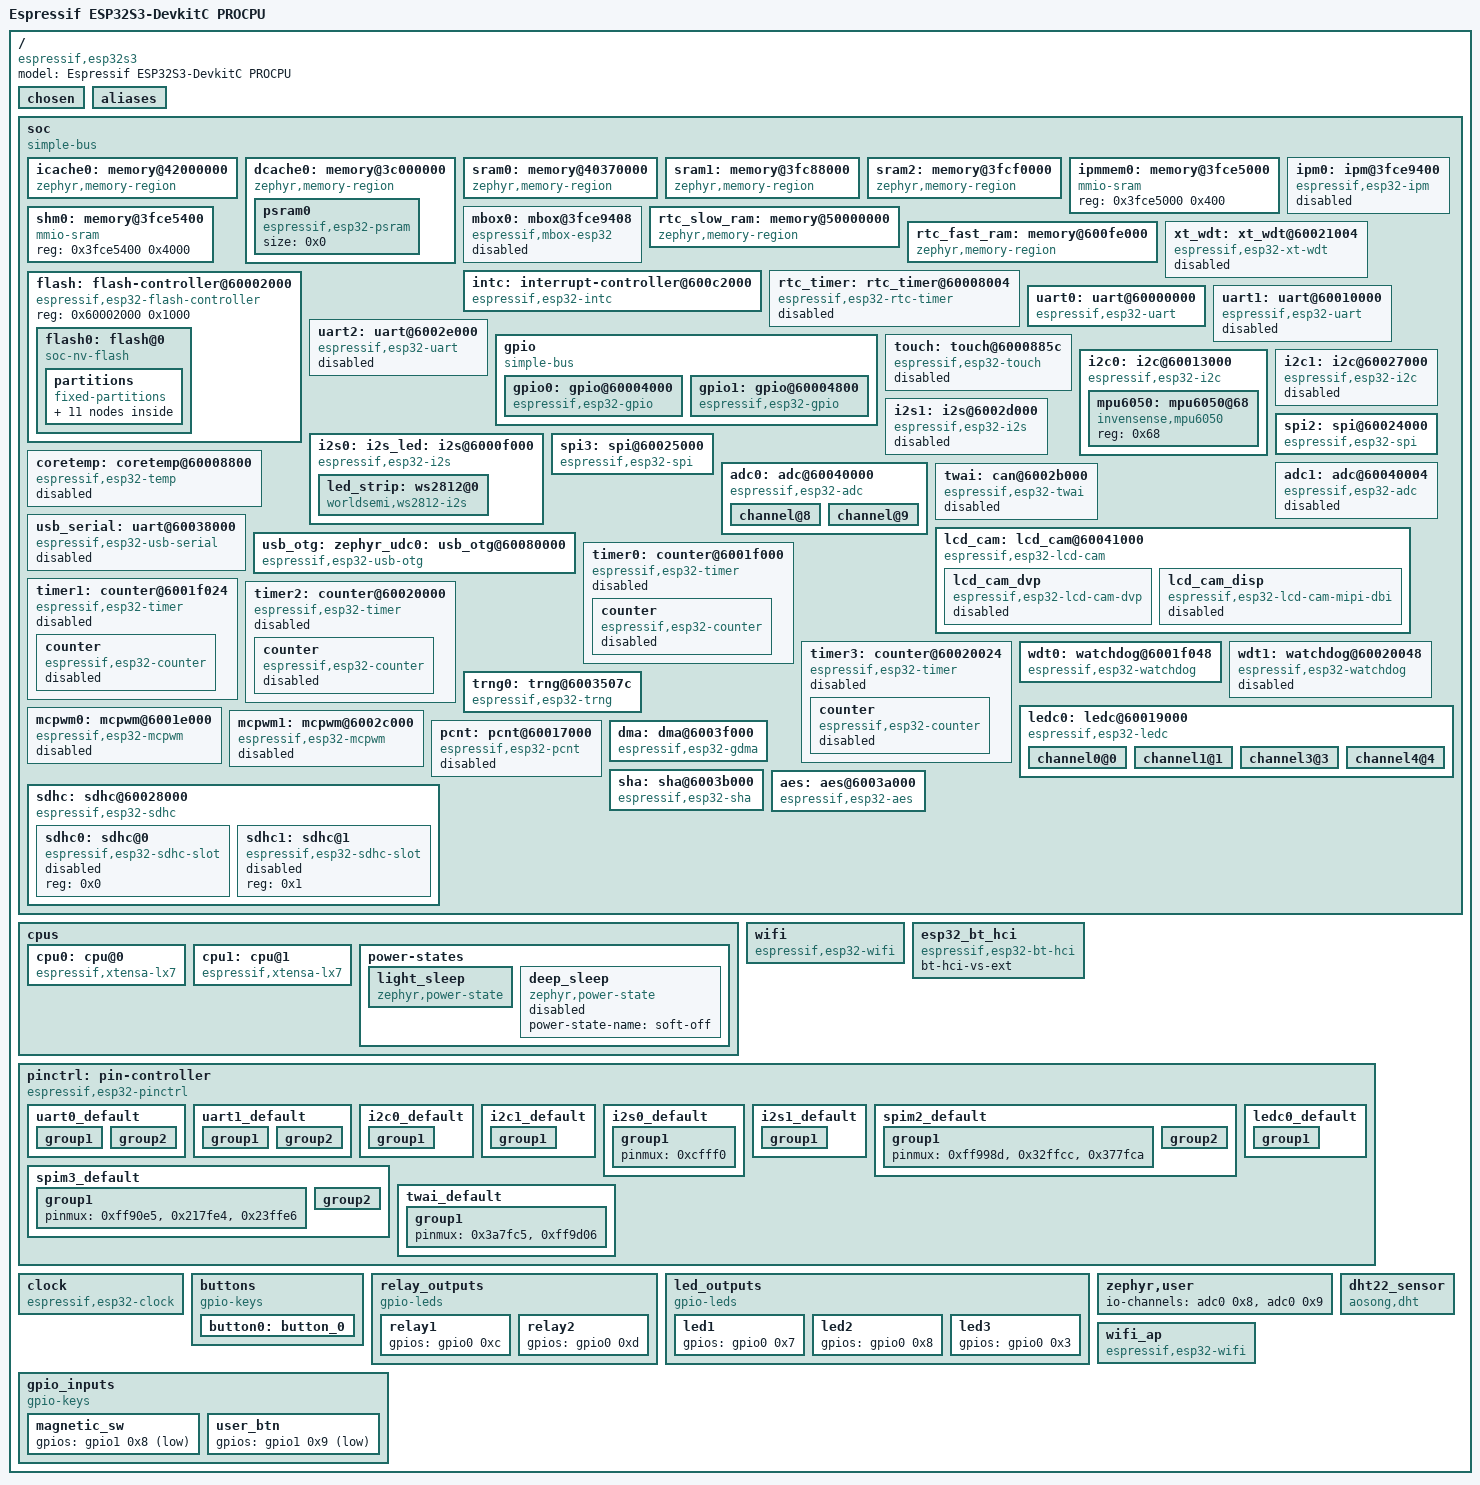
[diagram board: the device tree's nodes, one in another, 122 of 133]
/dts-v1/;

/* node '/' defined in zephyr/dts/common/skeleton.dtsi:9 */
/ {
	#address-cells = < 0x1 >;                   /* in zephyr/dts/common/skeleton.dtsi:10 */
	#size-cells = < 0x1 >;                      /* in zephyr/dts/common/skeleton.dtsi:11 */
	model = "Espressif ESP32S3-DevkitC PROCPU"; /* in zephyr/boards/espressif/esp32s3_devkitc/esp32s3_devkitc_procpu.dts:15 */
	compatible = "espressif,esp32s3";           /* in zephyr/boards/espressif/esp32s3_devkitc/esp32s3_devkitc_procpu.dts:16 */

	/* node '/chosen' defined in zephyr/dts/common/skeleton.dtsi:13 */
	chosen {
		zephyr,canbus = &twai;                    /* in zephyr/dts/xtensa/espressif/esp32s3/esp32s3_common.dtsi:22 */
		zephyr,entropy = &trng0;                  /* in zephyr/dts/xtensa/espressif/esp32s3/esp32s3_common.dtsi:23 */
		zephyr,flash-controller = &flash;         /* in zephyr/dts/xtensa/espressif/esp32s3/esp32s3_common.dtsi:24 */
		zephyr,sram = &sram1;                     /* in zephyr/boards/espressif/esp32s3_devkitc/esp32s3_devkitc_procpu.dts:26 */
		zephyr,console = &uart0;                  /* in zephyr/boards/espressif/esp32s3_devkitc/esp32s3_devkitc_procpu.dts:27 */
		zephyr,shell-uart = &uart0;               /* in zephyr/boards/espressif/esp32s3_devkitc/esp32s3_devkitc_procpu.dts:28 */
		zephyr,flash = &flash0;                   /* in zephyr/boards/espressif/esp32s3_devkitc/esp32s3_devkitc_procpu.dts:29 */
		zephyr,code-partition = &slot0_partition; /* in zephyr/boards/espressif/esp32s3_devkitc/esp32s3_devkitc_procpu.dts:30 */
		zephyr,bt-hci = &esp32_bt_hci;            /* in zephyr/boards/espressif/esp32s3_devkitc/esp32s3_devkitc_procpu.dts:31 */
	};

	/* node '/aliases' defined in zephyr/dts/common/skeleton.dtsi:15 */
	aliases {
		die-temp0 = &coretemp;  /* in zephyr/dts/xtensa/espressif/esp32s3/esp32s3_common.dtsi:18 */
		i2c-0 = &i2c0;          /* in zephyr/boards/espressif/esp32s3_devkitc/esp32s3_devkitc_procpu.dts:19 */
		watchdog0 = &wdt0;      /* in zephyr/boards/espressif/esp32s3_devkitc/esp32s3_devkitc_procpu.dts:20 */
		uart-0 = &uart0;        /* in zephyr/boards/espressif/esp32s3_devkitc/esp32s3_devkitc_procpu.dts:21 */
		sw0 = &button0;         /* in zephyr/boards/espressif/esp32s3_devkitc/esp32s3_devkitc_procpu.dts:22 */
		led-strip = &led_strip; /* in iot_interactive_kit/boards/esp32s3_devkitc_esp32s3_procpu.overlay:7 */
	};

	/* node '/soc' defined in zephyr/dts/xtensa/xtensa.dtsi:10 */
	soc {
		#address-cells = < 0x1 >;  /* in zephyr/dts/xtensa/espressif/esp32s3/esp32s3_common.dtsi:95 */
		#size-cells = < 0x1 >;     /* in zephyr/dts/xtensa/espressif/esp32s3/esp32s3_common.dtsi:96 */
		compatible = "simple-bus"; /* in zephyr/dts/xtensa/espressif/esp32s3/esp32s3_common.dtsi:97 */
		ranges;                    /* in zephyr/dts/xtensa/espressif/esp32s3/esp32s3_common.dtsi:98 */

		/* node '/soc/memory@42000000' defined in zephyr/dts/xtensa/espressif/esp32s3/esp32s3_common.dtsi:100 */
		icache0: memory@42000000 {
			compatible = "zephyr,memory-region"; /* in zephyr/dts/xtensa/espressif/esp32s3/esp32s3_common.dtsi:101 */
			reg = < 0x42000000 0x2000000 >;      /* in zephyr/dts/xtensa/espressif/esp32s3/esp32s3_common.dtsi:102 */
			zephyr,memory-region = "ICACHE0";    /* in zephyr/dts/xtensa/espressif/esp32s3/esp32s3_common.dtsi:103 */
		};

		/* node '/soc/memory@3c000000' defined in zephyr/dts/xtensa/espressif/esp32s3/esp32s3_common.dtsi:106 */
		dcache0: memory@3c000000 {
			compatible = "zephyr,memory-region"; /* in zephyr/dts/xtensa/espressif/esp32s3/esp32s3_common.dtsi:107 */
			reg = < 0x3c000000 0x2000000 >;      /* in zephyr/dts/xtensa/espressif/esp32s3/esp32s3_common.dtsi:108 */
			zephyr,memory-region = "DCACHE0";    /* in zephyr/dts/xtensa/espressif/esp32s3/esp32s3_common.dtsi:109 */

			/* node '/soc/memory@3c000000/psram0' defined in zephyr/dts/xtensa/espressif/esp32s3/esp32s3_common.dtsi:111 */
			psram0: psram0 {
				compatible = "espressif,esp32-psram"; /* in zephyr/dts/xtensa/espressif/esp32s3/esp32s3_common.dtsi:112 */
				size = < 0x0 >;                       /* in zephyr/dts/xtensa/espressif/esp32s3/esp32s3_common.dtsi:113 */
			};
		};

		/* node '/soc/memory@40370000' defined in zephyr/dts/xtensa/espressif/esp32s3/esp32s3_common.dtsi:117 */
		sram0: memory@40370000 {
			compatible = "zephyr,memory-region",
			             "mmio-sram";            /* in zephyr/dts/xtensa/espressif/esp32s3/esp32s3_common.dtsi:118 */
			reg = < 0x40370000 0x8000 >;         /* in zephyr/dts/xtensa/espressif/esp32s3/esp32s3_common.dtsi:119 */
			zephyr,memory-region = "SRAM0";      /* in zephyr/dts/xtensa/espressif/esp32s3/esp32s3_common.dtsi:120 */
		};

		/* node '/soc/memory@3fc88000' defined in zephyr/dts/xtensa/espressif/esp32s3/esp32s3_common.dtsi:123 */
		sram1: memory@3fc88000 {
			compatible = "zephyr,memory-region",
			             "mmio-sram";            /* in zephyr/dts/xtensa/espressif/esp32s3/esp32s3_common.dtsi:124 */
			reg = < 0x3fc88000 0x68000 >;        /* in zephyr/dts/xtensa/espressif/esp32s3/esp32s3_common.dtsi:125 */
			zephyr,memory-region = "SRAM1";      /* in zephyr/dts/xtensa/espressif/esp32s3/esp32s3_common.dtsi:126 */
		};

		/* node '/soc/memory@3fcf0000' defined in zephyr/dts/xtensa/espressif/esp32s3/esp32s3_common.dtsi:129 */
		sram2: memory@3fcf0000 {
			compatible = "zephyr,memory-region",
			             "mmio-sram";            /* in zephyr/dts/xtensa/espressif/esp32s3/esp32s3_common.dtsi:130 */
			reg = < 0x3fcf0000 0x10000 >;        /* in zephyr/dts/xtensa/espressif/esp32s3/esp32s3_common.dtsi:131 */
			zephyr,memory-region = "SRAM2";      /* in zephyr/dts/xtensa/espressif/esp32s3/esp32s3_common.dtsi:132 */
		};

		/* node '/soc/memory@3fce5000' defined in zephyr/dts/xtensa/espressif/esp32s3/esp32s3_common.dtsi:135 */
		ipmmem0: memory@3fce5000 {
			compatible = "mmio-sram";   /* in zephyr/dts/xtensa/espressif/esp32s3/esp32s3_common.dtsi:136 */
			reg = < 0x3fce5000 0x400 >; /* in zephyr/dts/xtensa/espressif/esp32s3/esp32s3_common.dtsi:137 */
			phandle = < 0x1 >;          /* in zephyr/dts/xtensa/espressif/esp32s3/esp32s3_common.dtsi:149 */
		};

		/* node '/soc/memory@3fce5400' defined in zephyr/dts/xtensa/espressif/esp32s3/esp32s3_common.dtsi:140 */
		shm0: memory@3fce5400 {
			compatible = "mmio-sram";    /* in zephyr/dts/xtensa/espressif/esp32s3/esp32s3_common.dtsi:141 */
			reg = < 0x3fce5400 0x4000 >; /* in zephyr/dts/xtensa/espressif/esp32s3/esp32s3_common.dtsi:142 */
		};

		/* node '/soc/ipm@3fce9400' defined in zephyr/dts/xtensa/espressif/esp32s3/esp32s3_common.dtsi:145 */
		ipm0: ipm@3fce9400 {
			compatible = "espressif,esp32-ipm"; /* in zephyr/dts/xtensa/espressif/esp32s3/esp32s3_common.dtsi:146 */
			reg = < 0x3fce9400 0x8 >;           /* in zephyr/dts/xtensa/espressif/esp32s3/esp32s3_common.dtsi:147 */
			status = "disabled";                /* in zephyr/dts/xtensa/espressif/esp32s3/esp32s3_common.dtsi:148 */
			shared-memory = < &ipmmem0 >;       /* in zephyr/dts/xtensa/espressif/esp32s3/esp32s3_common.dtsi:149 */
			shared-memory-size = < 0x400 >;     /* in zephyr/dts/xtensa/espressif/esp32s3/esp32s3_common.dtsi:150 */
			interrupts = < 0x4f 0x0 0x0 >,
			             < 0x50 0x0 0x0 >;      /* in zephyr/dts/xtensa/espressif/esp32s3/esp32s3_common.dtsi:151 */
			interrupt-parent = < &intc >;       /* in zephyr/dts/xtensa/espressif/esp32s3/esp32s3_common.dtsi:153 */
		};

		/* node '/soc/mbox@3fce9408' defined in zephyr/dts/xtensa/espressif/esp32s3/esp32s3_common.dtsi:156 */
		mbox0: mbox@3fce9408 {
			compatible = "espressif,mbox-esp32"; /* in zephyr/dts/xtensa/espressif/esp32s3/esp32s3_common.dtsi:157 */
			reg = < 0x3fce9408 0x8 >;            /* in zephyr/dts/xtensa/espressif/esp32s3/esp32s3_common.dtsi:158 */
			status = "disabled";                 /* in zephyr/dts/xtensa/espressif/esp32s3/esp32s3_common.dtsi:159 */
			shared-memory = < &ipmmem0 >;        /* in zephyr/dts/xtensa/espressif/esp32s3/esp32s3_common.dtsi:160 */
			shared-memory-size = < 0x400 >;      /* in zephyr/dts/xtensa/espressif/esp32s3/esp32s3_common.dtsi:161 */
			interrupts = < 0x4f 0x0 0x0 >,
			             < 0x50 0x0 0x0 >;       /* in zephyr/dts/xtensa/espressif/esp32s3/esp32s3_common.dtsi:162 */
			interrupt-parent = < &intc >;        /* in zephyr/dts/xtensa/espressif/esp32s3/esp32s3_common.dtsi:164 */
			#mbox-cells = < 0x1 >;               /* in zephyr/dts/xtensa/espressif/esp32s3/esp32s3_common.dtsi:165 */
		};

		/* node '/soc/memory@50000000' defined in zephyr/dts/xtensa/espressif/esp32s3/esp32s3_common.dtsi:168 */
		rtc_slow_ram: memory@50000000 {
			compatible = "zephyr,memory-region",
			             "mmio-sram";              /* in zephyr/dts/xtensa/espressif/esp32s3/esp32s3_common.dtsi:169 */
			reg = < 0x50000000 0x2000 >;           /* in zephyr/dts/xtensa/espressif/esp32s3/esp32s3_common.dtsi:170 */
			zephyr,memory-region = "RTC_SLOW_RAM"; /* in zephyr/dts/xtensa/espressif/esp32s3/esp32s3_common.dtsi:171 */
		};

		/* node '/soc/memory@600fe000' defined in zephyr/dts/xtensa/espressif/esp32s3/esp32s3_common.dtsi:174 */
		rtc_fast_ram: memory@600fe000 {
			compatible = "zephyr,memory-region",
			             "mmio-sram";              /* in zephyr/dts/xtensa/espressif/esp32s3/esp32s3_common.dtsi:175 */
			reg = < 0x600fe000 0x2000 >;           /* in zephyr/dts/xtensa/espressif/esp32s3/esp32s3_common.dtsi:176 */
			zephyr,memory-region = "RTC_FAST_RAM"; /* in zephyr/dts/xtensa/espressif/esp32s3/esp32s3_common.dtsi:177 */
		};

		/* node '/soc/interrupt-controller@600c2000' defined in zephyr/dts/xtensa/espressif/esp32s3/esp32s3_common.dtsi:180 */
		intc: interrupt-controller@600c2000 {
			#interrupt-cells = < 0x3 >;          /* in zephyr/dts/xtensa/espressif/esp32s3/esp32s3_common.dtsi:181 */
			#address-cells = < 0x0 >;            /* in zephyr/dts/xtensa/espressif/esp32s3/esp32s3_common.dtsi:182 */
			compatible = "espressif,esp32-intc"; /* in zephyr/dts/xtensa/espressif/esp32s3/esp32s3_common.dtsi:183 */
			interrupt-controller;                /* in zephyr/dts/xtensa/espressif/esp32s3/esp32s3_common.dtsi:184 */
			reg = < 0x600c2000 0x1000 >;         /* in zephyr/dts/xtensa/espressif/esp32s3/esp32s3_common.dtsi:185 */
			status = "okay";                     /* in zephyr/dts/xtensa/espressif/esp32s3/esp32s3_common.dtsi:186 */
			phandle = < 0x2 >;                   /* in zephyr/dts/xtensa/espressif/esp32s3/esp32s3_common.dtsi:153 */
		};

		/* node '/soc/xt_wdt@60021004' defined in zephyr/dts/xtensa/espressif/esp32s3/esp32s3_common.dtsi:189 */
		xt_wdt: xt_wdt@60021004 {
			compatible = "espressif,esp32-xt-wdt"; /* in zephyr/dts/xtensa/espressif/esp32s3/esp32s3_common.dtsi:190 */
			reg = < 0x60021004 0x4 >;              /* in zephyr/dts/xtensa/espressif/esp32s3/esp32s3_common.dtsi:191 */
			clocks = < &clock 0xc >;               /* in zephyr/dts/xtensa/espressif/esp32s3/esp32s3_common.dtsi:192 */
			interrupts = < 0x27 0x0 0x0 >;         /* in zephyr/dts/xtensa/espressif/esp32s3/esp32s3_common.dtsi:193 */
			interrupt-parent = < &intc >;          /* in zephyr/dts/xtensa/espressif/esp32s3/esp32s3_common.dtsi:194 */
			status = "disabled";                   /* in zephyr/dts/xtensa/espressif/esp32s3/esp32s3_common.dtsi:195 */
		};

		/* node '/soc/rtc_timer@60008004' defined in zephyr/dts/xtensa/espressif/esp32s3/esp32s3_common.dtsi:198 */
		rtc_timer: rtc_timer@60008004 {
			reg = < 0x60008004 0xc >;                 /* in zephyr/dts/xtensa/espressif/esp32s3/esp32s3_common.dtsi:199 */
			compatible = "espressif,esp32-rtc-timer"; /* in zephyr/dts/xtensa/espressif/esp32s3/esp32s3_common.dtsi:200 */
			clocks = < &clock 0xc >;                  /* in zephyr/dts/xtensa/espressif/esp32s3/esp32s3_common.dtsi:201 */
			interrupts = < 0x27 0x0 0x0 >;            /* in zephyr/dts/xtensa/espressif/esp32s3/esp32s3_common.dtsi:202 */
			interrupt-parent = < &intc >;             /* in zephyr/dts/xtensa/espressif/esp32s3/esp32s3_common.dtsi:203 */
			status = "disabled";                      /* in zephyr/dts/xtensa/espressif/esp32s3/esp32s3_common.dtsi:204 */
		};

		/* node '/soc/flash-controller@60002000' defined in zephyr/dts/xtensa/espressif/esp32s3/esp32s3_common.dtsi:207 */
		flash: flash-controller@60002000 {
			compatible = "espressif,esp32-flash-controller"; /* in zephyr/dts/xtensa/espressif/esp32s3/esp32s3_common.dtsi:208 */
			reg = < 0x60002000 0x1000 >;                     /* in zephyr/dts/xtensa/espressif/esp32s3/esp32s3_common.dtsi:209 */
			#address-cells = < 0x1 >;                        /* in zephyr/dts/xtensa/espressif/esp32s3/esp32s3_common.dtsi:210 */
			#size-cells = < 0x1 >;                           /* in zephyr/dts/xtensa/espressif/esp32s3/esp32s3_common.dtsi:211 */

			/* node '/soc/flash-controller@60002000/flash@0' defined in zephyr/dts/xtensa/espressif/esp32s3/esp32s3_common.dtsi:213 */
			flash0: flash@0 {
				compatible = "soc-nv-flash";   /* in zephyr/dts/xtensa/espressif/esp32s3/esp32s3_common.dtsi:214 */
				erase-block-size = < 0x1000 >; /* in zephyr/dts/xtensa/espressif/esp32s3/esp32s3_common.dtsi:215 */
				write-block-size = < 0x4 >;    /* in zephyr/dts/xtensa/espressif/esp32s3/esp32s3_common.dtsi:216 */
				reg = < 0x0 0x800000 >;        /* in zephyr/dts/xtensa/espressif/esp32s3/esp32s3_wroom_n8.dtsi:11 */

				/* node '/soc/flash-controller@60002000/flash@0/partitions' defined in zephyr/dts/vendor/espressif/partitions_0x0_amp_4M.dtsi:8 */
				partitions {
					compatible = "fixed-partitions"; /* in zephyr/dts/vendor/espressif/partitions_0x0_amp_4M.dtsi:9 */
					#address-cells = < 0x1 >;        /* in zephyr/dts/vendor/espressif/partitions_0x0_amp_4M.dtsi:10 */
					#size-cells = < 0x1 >;           /* in zephyr/dts/vendor/espressif/partitions_0x0_amp_4M.dtsi:11 */

					/* node '/soc/flash-controller@60002000/flash@0/partitions/partition@0' defined in zephyr/dts/vendor/espressif/partitions_0x0_amp_4M.dtsi:13 */
					boot_partition: partition@0 {
						label = "mcuboot";     /* in zephyr/dts/vendor/espressif/partitions_0x0_amp_4M.dtsi:14 */
						reg = < 0x0 0x10000 >; /* in zephyr/dts/vendor/espressif/partitions_0x0_amp_4M.dtsi:15 */
					};

					/* node '/soc/flash-controller@60002000/flash@0/partitions/partition@10000' defined in zephyr/dts/vendor/espressif/partitions_0x0_amp_4M.dtsi:18 */
					sys_partition: partition@10000 {
						label = "sys";             /* in zephyr/dts/vendor/espressif/partitions_0x0_amp_4M.dtsi:19 */
						reg = < 0x10000 0x10000 >; /* in zephyr/dts/vendor/espressif/partitions_0x0_amp_4M.dtsi:20 */
					};

					/* node '/soc/flash-controller@60002000/flash@0/partitions/partition@20000' defined in zephyr/dts/vendor/espressif/partitions_0x0_amp_4M.dtsi:23 */
					slot0_partition: partition@20000 {
						label = "image-0";          /* in zephyr/dts/vendor/espressif/partitions_0x0_amp_4M.dtsi:24 */
						reg = < 0x20000 0x150000 >; /* in zephyr/dts/vendor/espressif/partitions_0x0_amp_4M.dtsi:25 */
					};

					/* node '/soc/flash-controller@60002000/flash@0/partitions/partition@170000' defined in zephyr/dts/vendor/espressif/partitions_0x0_amp_4M.dtsi:28 */
					slot1_partition: partition@170000 {
						label = "image-1";           /* in zephyr/dts/vendor/espressif/partitions_0x0_amp_4M.dtsi:29 */
						reg = < 0x170000 0x150000 >; /* in zephyr/dts/vendor/espressif/partitions_0x0_amp_4M.dtsi:30 */
					};

					/* node '/soc/flash-controller@60002000/flash@0/partitions/partition@2c0000' defined in zephyr/dts/vendor/espressif/partitions_0x0_amp_4M.dtsi:33 */
					slot0_appcpu_partition: partition@2c0000 {
						label = "image-0-appcpu";   /* in zephyr/dts/vendor/espressif/partitions_0x0_amp_4M.dtsi:34 */
						reg = < 0x2c0000 0x70000 >; /* in zephyr/dts/vendor/espressif/partitions_0x0_amp_4M.dtsi:35 */
					};

					/* node '/soc/flash-controller@60002000/flash@0/partitions/partition@330000' defined in zephyr/dts/vendor/espressif/partitions_0x0_amp_4M.dtsi:38 */
					slot1_appcpu_partition: partition@330000 {
						label = "image-1-appcpu";   /* in zephyr/dts/vendor/espressif/partitions_0x0_amp_4M.dtsi:39 */
						reg = < 0x330000 0x70000 >; /* in zephyr/dts/vendor/espressif/partitions_0x0_amp_4M.dtsi:40 */
					};

					/* node '/soc/flash-controller@60002000/flash@0/partitions/partition@3a0000' defined in zephyr/dts/vendor/espressif/partitions_0x0_amp_4M.dtsi:43 */
					slot0_lpcore_partition: partition@3a0000 {
						label = "image-0-lpcore";  /* in zephyr/dts/vendor/espressif/partitions_0x0_amp_4M.dtsi:44 */
						reg = < 0x3a0000 0x8000 >; /* in zephyr/dts/vendor/espressif/partitions_0x0_amp_4M.dtsi:45 */
					};

					/* node '/soc/flash-controller@60002000/flash@0/partitions/partition@3a8000' defined in zephyr/dts/vendor/espressif/partitions_0x0_amp_4M.dtsi:48 */
					slot1_lpcore_partition: partition@3a8000 {
						label = "image-1-lpcore";  /* in zephyr/dts/vendor/espressif/partitions_0x0_amp_4M.dtsi:49 */
						reg = < 0x3a8000 0x8000 >; /* in zephyr/dts/vendor/espressif/partitions_0x0_amp_4M.dtsi:50 */
					};

					/* node '/soc/flash-controller@60002000/flash@0/partitions/partition@3b0000' defined in zephyr/dts/vendor/espressif/partitions_0x0_amp_4M.dtsi:53 */
					storage_partition: partition@3b0000 {
						label = "storage";          /* in zephyr/dts/vendor/espressif/partitions_0x0_amp_4M.dtsi:54 */
						reg = < 0x3b0000 0x30000 >; /* in zephyr/dts/vendor/espressif/partitions_0x0_amp_4M.dtsi:55 */
					};

					/* node '/soc/flash-controller@60002000/flash@0/partitions/partition@3e0000' defined in zephyr/dts/vendor/espressif/partitions_0x0_amp_4M.dtsi:58 */
					scratch_partition: partition@3e0000 {
						label = "image-scratch";    /* in zephyr/dts/vendor/espressif/partitions_0x0_amp_4M.dtsi:59 */
						reg = < 0x3e0000 0x1f000 >; /* in zephyr/dts/vendor/espressif/partitions_0x0_amp_4M.dtsi:60 */
					};

					/* node '/soc/flash-controller@60002000/flash@0/partitions/partition@3ff000' defined in zephyr/dts/vendor/espressif/partitions_0x0_amp_4M.dtsi:63 */
					coredump_partition: partition@3ff000 {
						label = "coredump";        /* in zephyr/dts/vendor/espressif/partitions_0x0_amp_4M.dtsi:64 */
						reg = < 0x3ff000 0x1000 >; /* in zephyr/dts/vendor/espressif/partitions_0x0_amp_4M.dtsi:65 */
					};
				};
			};
		};

		/* node '/soc/uart@60000000' defined in zephyr/dts/xtensa/espressif/esp32s3/esp32s3_common.dtsi:221 */
		uart0: uart@60000000 {
			compatible = "espressif,esp32-uart"; /* in zephyr/dts/xtensa/espressif/esp32s3/esp32s3_common.dtsi:222 */
			reg = < 0x60000000 0x1000 >;         /* in zephyr/dts/xtensa/espressif/esp32s3/esp32s3_common.dtsi:223 */
			interrupts = < 0x1b 0x0 0x0 >;       /* in zephyr/dts/xtensa/espressif/esp32s3/esp32s3_common.dtsi:224 */
			interrupt-parent = < &intc >;        /* in zephyr/dts/xtensa/espressif/esp32s3/esp32s3_common.dtsi:225 */
			clocks = < &clock 0x65 >;            /* in zephyr/dts/xtensa/espressif/esp32s3/esp32s3_common.dtsi:226 */
			status = "okay";                     /* in zephyr/boards/espressif/esp32s3_devkitc/esp32s3_devkitc_procpu.dts:50 */
			current-speed = < 0x1c200 >;         /* in zephyr/boards/espressif/esp32s3_devkitc/esp32s3_devkitc_procpu.dts:51 */
			pinctrl-0 = < &uart0_default >;      /* in zephyr/boards/espressif/esp32s3_devkitc/esp32s3_devkitc_procpu.dts:52 */
			pinctrl-names = "default";           /* in zephyr/boards/espressif/esp32s3_devkitc/esp32s3_devkitc_procpu.dts:53 */
		};

		/* node '/soc/uart@60010000' defined in zephyr/dts/xtensa/espressif/esp32s3/esp32s3_common.dtsi:230 */
		uart1: uart@60010000 {
			compatible = "espressif,esp32-uart"; /* in zephyr/dts/xtensa/espressif/esp32s3/esp32s3_common.dtsi:231 */
			reg = < 0x60010000 0x1000 >;         /* in zephyr/dts/xtensa/espressif/esp32s3/esp32s3_common.dtsi:232 */
			interrupts = < 0x1c 0x0 0x0 >;       /* in zephyr/dts/xtensa/espressif/esp32s3/esp32s3_common.dtsi:233 */
			interrupt-parent = < &intc >;        /* in zephyr/dts/xtensa/espressif/esp32s3/esp32s3_common.dtsi:234 */
			clocks = < &clock 0x0 >;             /* in zephyr/dts/xtensa/espressif/esp32s3/esp32s3_common.dtsi:235 */
			status = "disabled";                 /* in zephyr/dts/xtensa/espressif/esp32s3/esp32s3_common.dtsi:236 */
		};

		/* node '/soc/uart@6002e000' defined in zephyr/dts/xtensa/espressif/esp32s3/esp32s3_common.dtsi:239 */
		uart2: uart@6002e000 {
			compatible = "espressif,esp32-uart"; /* in zephyr/dts/xtensa/espressif/esp32s3/esp32s3_common.dtsi:240 */
			reg = < 0x6002e000 0x1000 >;         /* in zephyr/dts/xtensa/espressif/esp32s3/esp32s3_common.dtsi:241 */
			interrupts = < 0x1d 0x0 0x0 >;       /* in zephyr/dts/xtensa/espressif/esp32s3/esp32s3_common.dtsi:242 */
			interrupt-parent = < &intc >;        /* in zephyr/dts/xtensa/espressif/esp32s3/esp32s3_common.dtsi:243 */
			clocks = < &clock 0x1 >;             /* in zephyr/dts/xtensa/espressif/esp32s3/esp32s3_common.dtsi:244 */
			status = "disabled";                 /* in zephyr/dts/xtensa/espressif/esp32s3/esp32s3_common.dtsi:245 */
		};

		/* node '/soc/gpio' defined in zephyr/dts/xtensa/espressif/esp32s3/esp32s3_common.dtsi:248 */
		gpio: gpio {
			compatible = "simple-bus";                                     /* in zephyr/dts/xtensa/espressif/esp32s3/esp32s3_common.dtsi:249 */
			gpio-map-mask = < 0xffffffe0 0xffffffc0 >;                     /* in zephyr/dts/xtensa/espressif/esp32s3/esp32s3_common.dtsi:250 */
			gpio-map-pass-thru = < 0x1f 0x3f >;                            /* in zephyr/dts/xtensa/espressif/esp32s3/esp32s3_common.dtsi:251 */
			gpio-map = < 0x0 0x0 &gpio0 0x0 0x0 0x20 0x0 &gpio1 0x0 0x0 >; /* in zephyr/dts/xtensa/espressif/esp32s3/esp32s3_common.dtsi:252 */
			#gpio-cells = < 0x2 >;                                         /* in zephyr/dts/xtensa/espressif/esp32s3/esp32s3_common.dtsi:254 */
			#address-cells = < 0x1 >;                                      /* in zephyr/dts/xtensa/espressif/esp32s3/esp32s3_common.dtsi:255 */
			#size-cells = < 0x1 >;                                         /* in zephyr/dts/xtensa/espressif/esp32s3/esp32s3_common.dtsi:256 */
			ranges;                                                        /* in zephyr/dts/xtensa/espressif/esp32s3/esp32s3_common.dtsi:257 */

			/* node '/soc/gpio/gpio@60004000' defined in zephyr/dts/xtensa/espressif/esp32s3/esp32s3_common.dtsi:259 */
			gpio0: gpio@60004000 {
				compatible = "espressif,esp32-gpio"; /* in zephyr/dts/xtensa/espressif/esp32s3/esp32s3_common.dtsi:260 */
				gpio-controller;                     /* in zephyr/dts/xtensa/espressif/esp32s3/esp32s3_common.dtsi:261 */
				#gpio-cells = < 0x2 >;               /* in zephyr/dts/xtensa/espressif/esp32s3/esp32s3_common.dtsi:262 */
				reg = < 0x60004000 0x800 >;          /* in zephyr/dts/xtensa/espressif/esp32s3/esp32s3_common.dtsi:263 */
				interrupts = < 0x10 0x0 0x0 >;       /* in zephyr/dts/xtensa/espressif/esp32s3/esp32s3_common.dtsi:264 */
				interrupt-parent = < &intc >;        /* in zephyr/dts/xtensa/espressif/esp32s3/esp32s3_common.dtsi:265 */
				ngpios = < 0x20 >;                   /* in zephyr/dts/xtensa/espressif/esp32s3/esp32s3_common.dtsi:271 */
				status = "okay";                     /* in zephyr/boards/espressif/esp32s3_devkitc/esp32s3_devkitc_procpu.dts:57 */
				phandle = < 0x5 >;                   /* in zephyr/dts/xtensa/espressif/esp32s3/esp32s3_common.dtsi:252 */
			};

			/* node '/soc/gpio/gpio@60004800' defined in zephyr/dts/xtensa/espressif/esp32s3/esp32s3_common.dtsi:274 */
			gpio1: gpio@60004800 {
				compatible = "espressif,esp32-gpio"; /* in zephyr/dts/xtensa/espressif/esp32s3/esp32s3_common.dtsi:275 */
				gpio-controller;                     /* in zephyr/dts/xtensa/espressif/esp32s3/esp32s3_common.dtsi:276 */
				#gpio-cells = < 0x2 >;               /* in zephyr/dts/xtensa/espressif/esp32s3/esp32s3_common.dtsi:277 */
				reg = < 0x60004800 0x800 >;          /* in zephyr/dts/xtensa/espressif/esp32s3/esp32s3_common.dtsi:278 */
				interrupts = < 0x10 0x0 0x0 >;       /* in zephyr/dts/xtensa/espressif/esp32s3/esp32s3_common.dtsi:279 */
				interrupt-parent = < &intc >;        /* in zephyr/dts/xtensa/espressif/esp32s3/esp32s3_common.dtsi:280 */
				ngpios = < 0x16 >;                   /* in zephyr/dts/xtensa/espressif/esp32s3/esp32s3_common.dtsi:281 */
				status = "okay";                     /* in zephyr/boards/espressif/esp32s3_devkitc/esp32s3_devkitc_procpu.dts:61 */
				phandle = < 0x6 >;                   /* in zephyr/dts/xtensa/espressif/esp32s3/esp32s3_common.dtsi:252 */
			};
		};

		/* node '/soc/touch@6000885c' defined in zephyr/dts/xtensa/espressif/esp32s3/esp32s3_common.dtsi:285 */
		touch: touch@6000885c {
			compatible = "espressif,esp32-touch";      /* in zephyr/dts/xtensa/espressif/esp32s3/esp32s3_common.dtsi:286 */
			reg = < 0x6000885c 0x88 0x60008908 0x18 >; /* in zephyr/dts/xtensa/espressif/esp32s3/esp32s3_common.dtsi:287 */
			interrupts = < 0x27 0x0 0x0 >;             /* in zephyr/dts/xtensa/espressif/esp32s3/esp32s3_common.dtsi:288 */
			interrupt-parent = < &intc >;              /* in zephyr/dts/xtensa/espressif/esp32s3/esp32s3_common.dtsi:289 */
			status = "disabled";                       /* in zephyr/dts/xtensa/espressif/esp32s3/esp32s3_common.dtsi:290 */
			debounce-interval-ms = < 0x1e >;           /* in zephyr/boards/espressif/esp32s3_devkitc/esp32s3_devkitc_procpu.dts:65 */
			href-microvolt = < 0x2932e0 >;             /* in zephyr/boards/espressif/esp32s3_devkitc/esp32s3_devkitc_procpu.dts:66 */
			lref-microvolt = < 0x7a120 >;              /* in zephyr/boards/espressif/esp32s3_devkitc/esp32s3_devkitc_procpu.dts:67 */
			href-atten-microvolt = < 0xf4240 >;        /* in zephyr/boards/espressif/esp32s3_devkitc/esp32s3_devkitc_procpu.dts:68 */
			filter-mode = < 0x2 >;                     /* in zephyr/boards/espressif/esp32s3_devkitc/esp32s3_devkitc_procpu.dts:69 */
			filter-debounce-cnt = < 0x1 >;             /* in zephyr/boards/espressif/esp32s3_devkitc/esp32s3_devkitc_procpu.dts:70 */
			filter-noise-thr = < 0x0 >;                /* in zephyr/boards/espressif/esp32s3_devkitc/esp32s3_devkitc_procpu.dts:71 */
			filter-jitter-step = < 0x4 >;              /* in zephyr/boards/espressif/esp32s3_devkitc/esp32s3_devkitc_procpu.dts:72 */
			filter-smooth-level = < 0x1 >;             /* in zephyr/boards/espressif/esp32s3_devkitc/esp32s3_devkitc_procpu.dts:73 */
		};

		/* node '/soc/i2c@60013000' defined in zephyr/dts/xtensa/espressif/esp32s3/esp32s3_common.dtsi:293 */
		i2c0: i2c@60013000 {
			compatible = "espressif,esp32-i2c"; /* in zephyr/dts/xtensa/espressif/esp32s3/esp32s3_common.dtsi:294 */
			#address-cells = < 0x1 >;           /* in zephyr/dts/xtensa/espressif/esp32s3/esp32s3_common.dtsi:295 */
			#size-cells = < 0x0 >;              /* in zephyr/dts/xtensa/espressif/esp32s3/esp32s3_common.dtsi:296 */
			reg = < 0x60013000 0x1000 >;        /* in zephyr/dts/xtensa/espressif/esp32s3/esp32s3_common.dtsi:297 */
			interrupts = < 0x2a 0x0 0x0 >;      /* in zephyr/dts/xtensa/espressif/esp32s3/esp32s3_common.dtsi:298 */
			interrupt-parent = < &intc >;       /* in zephyr/dts/xtensa/espressif/esp32s3/esp32s3_common.dtsi:299 */
			clocks = < &clock 0x67 >;           /* in zephyr/dts/xtensa/espressif/esp32s3/esp32s3_common.dtsi:300 */
			status = "okay";                    /* in iot_interactive_kit/boards/esp32s3_devkitc_esp32s3_procpu.overlay:134 */
			clock-frequency = < 0x186a0 >;      /* in iot_interactive_kit/boards/esp32s3_devkitc_esp32s3_procpu.overlay:135 */
			pinctrl-0 = < &i2c0_default >;      /* in iot_interactive_kit/boards/esp32s3_devkitc_esp32s3_procpu.overlay:136 */
			pinctrl-names = "default";          /* in iot_interactive_kit/boards/esp32s3_devkitc_esp32s3_procpu.overlay:137 */

			/* node '/soc/i2c@60013000/mpu6050@68' defined in iot_interactive_kit/boards/esp32s3_devkitc_esp32s3_procpu.overlay:139 */
			mpu6050: mpu6050@68 {
				compatible = "invensense,mpu6050"; /* in iot_interactive_kit/boards/esp32s3_devkitc_esp32s3_procpu.overlay:140 */
				reg = < 0x68 >;                    /* in iot_interactive_kit/boards/esp32s3_devkitc_esp32s3_procpu.overlay:141 */
				status = "okay";                   /* in iot_interactive_kit/boards/esp32s3_devkitc_esp32s3_procpu.overlay:142 */
			};
		};

		/* node '/soc/i2c@60027000' defined in zephyr/dts/xtensa/espressif/esp32s3/esp32s3_common.dtsi:304 */
		i2c1: i2c@60027000 {
			compatible = "espressif,esp32-i2c"; /* in zephyr/dts/xtensa/espressif/esp32s3/esp32s3_common.dtsi:305 */
			#address-cells = < 0x1 >;           /* in zephyr/dts/xtensa/espressif/esp32s3/esp32s3_common.dtsi:306 */
			#size-cells = < 0x0 >;              /* in zephyr/dts/xtensa/espressif/esp32s3/esp32s3_common.dtsi:307 */
			reg = < 0x60027000 0x1000 >;        /* in zephyr/dts/xtensa/espressif/esp32s3/esp32s3_common.dtsi:308 */
			interrupts = < 0x2b 0x0 0x0 >;      /* in zephyr/dts/xtensa/espressif/esp32s3/esp32s3_common.dtsi:309 */
			interrupt-parent = < &intc >;       /* in zephyr/dts/xtensa/espressif/esp32s3/esp32s3_common.dtsi:310 */
			clocks = < &clock 0x68 >;           /* in zephyr/dts/xtensa/espressif/esp32s3/esp32s3_common.dtsi:311 */
			status = "disabled";                /* in zephyr/dts/xtensa/espressif/esp32s3/esp32s3_common.dtsi:312 */
			clock-frequency = < 0x186a0 >;      /* in zephyr/boards/espressif/esp32s3_devkitc/esp32s3_devkitc_procpu.dts:83 */
			pinctrl-0 = < &i2c1_default >;      /* in zephyr/boards/espressif/esp32s3_devkitc/esp32s3_devkitc_procpu.dts:84 */
			pinctrl-names = "default";          /* in zephyr/boards/espressif/esp32s3_devkitc/esp32s3_devkitc_procpu.dts:85 */
		};

		/* node '/soc/i2s@6000f000' defined in zephyr/dts/xtensa/espressif/esp32s3/esp32s3_common.dtsi:315 */
		i2s0: i2s_led: i2s@6000f000 {
			compatible = "espressif,esp32-i2s"; /* in zephyr/dts/xtensa/espressif/esp32s3/esp32s3_common.dtsi:316 */
			#address-cells = < 0x1 >;           /* in zephyr/dts/xtensa/espressif/esp32s3/esp32s3_common.dtsi:317 */
			#size-cells = < 0x0 >;              /* in zephyr/dts/xtensa/espressif/esp32s3/esp32s3_common.dtsi:318 */
			reg = < 0x6000f000 0x1000 >;        /* in zephyr/dts/xtensa/espressif/esp32s3/esp32s3_common.dtsi:319 */
			interrupts = < 0x19 0x0 0x0 >;      /* in zephyr/dts/xtensa/espressif/esp32s3/esp32s3_common.dtsi:320 */
			interrupt-parent = < &intc >;       /* in zephyr/dts/xtensa/espressif/esp32s3/esp32s3_common.dtsi:321 */
			clocks = < &clock 0x69 >;           /* in zephyr/dts/xtensa/espressif/esp32s3/esp32s3_common.dtsi:322 */
			unit = < 0x0 >;                     /* in zephyr/dts/xtensa/espressif/esp32s3/esp32s3_common.dtsi:325 */
			pinctrl-0 = < &i2s0_default >;      /* in zephyr/boards/espressif/esp32s3_devkitc/esp32s3_devkitc_procpu.dts:89 */
			pinctrl-names = "default";          /* in zephyr/boards/espressif/esp32s3_devkitc/esp32s3_devkitc_procpu.dts:90 */
			status = "okay";                    /* in iot_interactive_kit/boards/esp32s3_devkitc_esp32s3_procpu.overlay:76 */
			dmas = < &dma 0x3 >;                /* in iot_interactive_kit/boards/esp32s3_devkitc_esp32s3_procpu.overlay:78 */
			dma-names = "tx";                   /* in iot_interactive_kit/boards/esp32s3_devkitc_esp32s3_procpu.overlay:79 */

			/* node '/soc/i2s@6000f000/ws2812@0' defined in iot_interactive_kit/boards/esp32s3_devkitc_esp32s3_procpu.overlay:81 */
			led_strip: ws2812@0 {
				compatible = "worldsemi,ws2812-i2s"; /* in iot_interactive_kit/boards/esp32s3_devkitc_esp32s3_procpu.overlay:82 */
				reg = < 0x0 >;                       /* in iot_interactive_kit/boards/esp32s3_devkitc_esp32s3_procpu.overlay:84 */
				chain-length = < 0x1 >;              /* in iot_interactive_kit/boards/esp32s3_devkitc_esp32s3_procpu.overlay:85 */
				color-mapping = < 0x2 0x1 0x3 >;     /* in iot_interactive_kit/boards/esp32s3_devkitc_esp32s3_procpu.overlay:86 */
				reset-delay = < 0x1f4 >;             /* in iot_interactive_kit/boards/esp32s3_devkitc_esp32s3_procpu.overlay:89 */
			};
		};

		/* node '/soc/i2s@6002d000' defined in zephyr/dts/xtensa/espressif/esp32s3/esp32s3_common.dtsi:329 */
		i2s1: i2s@6002d000 {
			compatible = "espressif,esp32-i2s"; /* in zephyr/dts/xtensa/espressif/esp32s3/esp32s3_common.dtsi:330 */
			#address-cells = < 0x1 >;           /* in zephyr/dts/xtensa/espressif/esp32s3/esp32s3_common.dtsi:331 */
			#size-cells = < 0x0 >;              /* in zephyr/dts/xtensa/espressif/esp32s3/esp32s3_common.dtsi:332 */
			reg = < 0x6002d000 0x1000 >;        /* in zephyr/dts/xtensa/espressif/esp32s3/esp32s3_common.dtsi:333 */
			interrupts = < 0x1a 0x0 0x0 >;      /* in zephyr/dts/xtensa/espressif/esp32s3/esp32s3_common.dtsi:334 */
			interrupt-parent = < &intc >;       /* in zephyr/dts/xtensa/espressif/esp32s3/esp32s3_common.dtsi:335 */
			clocks = < &clock 0x6a >;           /* in zephyr/dts/xtensa/espressif/esp32s3/esp32s3_common.dtsi:336 */
			dmas = < &dma 0x4 >,
			       < &dma 0x5 >;                /* in zephyr/dts/xtensa/espressif/esp32s3/esp32s3_common.dtsi:337 */
			dma-names = "rx",
			            "tx";                   /* in zephyr/dts/xtensa/espressif/esp32s3/esp32s3_common.dtsi:338 */
			unit = < 0x1 >;                     /* in zephyr/dts/xtensa/espressif/esp32s3/esp32s3_common.dtsi:339 */
			status = "disabled";                /* in zephyr/dts/xtensa/espressif/esp32s3/esp32s3_common.dtsi:340 */
			pinctrl-0 = < &i2s1_default >;      /* in zephyr/boards/espressif/esp32s3_devkitc/esp32s3_devkitc_procpu.dts:94 */
			pinctrl-names = "default";          /* in zephyr/boards/espressif/esp32s3_devkitc/esp32s3_devkitc_procpu.dts:95 */
		};

		/* node '/soc/spi@60024000' defined in zephyr/dts/xtensa/espressif/esp32s3/esp32s3_common.dtsi:343 */
		spi2: spi@60024000 {
			compatible = "espressif,esp32-spi"; /* in zephyr/dts/xtensa/espressif/esp32s3/esp32s3_common.dtsi:344 */
			reg = < 0x60024000 0x1000 >;        /* in zephyr/dts/xtensa/espressif/esp32s3/esp32s3_common.dtsi:345 */
			interrupts = < 0x15 0x0 0x0 >;      /* in zephyr/dts/xtensa/espressif/esp32s3/esp32s3_common.dtsi:346 */
			interrupt-parent = < &intc >;       /* in zephyr/dts/xtensa/espressif/esp32s3/esp32s3_common.dtsi:347 */
			clocks = < &clock 0x73 >;           /* in zephyr/dts/xtensa/espressif/esp32s3/esp32s3_common.dtsi:348 */
			dma-host = < 0x0 >;                 /* in zephyr/dts/xtensa/espressif/esp32s3/esp32s3_common.dtsi:349 */
			#address-cells = < 0x1 >;           /* in zephyr/boards/espressif/esp32s3_devkitc/esp32s3_devkitc_procpu.dts:99 */
			#size-cells = < 0x0 >;              /* in zephyr/boards/espressif/esp32s3_devkitc/esp32s3_devkitc_procpu.dts:100 */
			status = "okay";                    /* in zephyr/boards/espressif/esp32s3_devkitc/esp32s3_devkitc_procpu.dts:101 */
			pinctrl-0 = < &spim2_default >;     /* in zephyr/boards/espressif/esp32s3_devkitc/esp32s3_devkitc_procpu.dts:102 */
			pinctrl-names = "default";          /* in zephyr/boards/espressif/esp32s3_devkitc/esp32s3_devkitc_procpu.dts:103 */
		};

		/* node '/soc/spi@60025000' defined in zephyr/dts/xtensa/espressif/esp32s3/esp32s3_common.dtsi:353 */
		spi3: spi@60025000 {
			compatible = "espressif,esp32-spi"; /* in zephyr/dts/xtensa/espressif/esp32s3/esp32s3_common.dtsi:354 */
			reg = < 0x60025000 0x1000 >;        /* in zephyr/dts/xtensa/espressif/esp32s3/esp32s3_common.dtsi:355 */
			interrupts = < 0x16 0x0 0x0 >;      /* in zephyr/dts/xtensa/espressif/esp32s3/esp32s3_common.dtsi:356 */
			interrupt-parent = < &intc >;       /* in zephyr/dts/xtensa/espressif/esp32s3/esp32s3_common.dtsi:357 */
			clocks = < &clock 0x74 >;           /* in zephyr/dts/xtensa/espressif/esp32s3/esp32s3_common.dtsi:358 */
			dma-host = < 0x1 >;                 /* in zephyr/dts/xtensa/espressif/esp32s3/esp32s3_common.dtsi:359 */
			#address-cells = < 0x1 >;           /* in zephyr/boards/espressif/esp32s3_devkitc/esp32s3_devkitc_procpu.dts:107 */
			#size-cells = < 0x0 >;              /* in zephyr/boards/espressif/esp32s3_devkitc/esp32s3_devkitc_procpu.dts:108 */
			status = "okay";                    /* in zephyr/boards/espressif/esp32s3_devkitc/esp32s3_devkitc_procpu.dts:109 */
			pinctrl-0 = < &spim3_default >;     /* in zephyr/boards/espressif/esp32s3_devkitc/esp32s3_devkitc_procpu.dts:110 */
			pinctrl-names = "default";          /* in zephyr/boards/espressif/esp32s3_devkitc/esp32s3_devkitc_procpu.dts:111 */
		};

		/* node '/soc/coretemp@60008800' defined in zephyr/dts/xtensa/espressif/esp32s3/esp32s3_common.dtsi:363 */
		coretemp: coretemp@60008800 {
			compatible = "espressif,esp32-temp"; /* in zephyr/dts/xtensa/espressif/esp32s3/esp32s3_common.dtsi:364 */
			friendly-name = "coretemp";          /* in zephyr/dts/xtensa/espressif/esp32s3/esp32s3_common.dtsi:365 */
			reg = < 0x60008800 0x4 >;            /* in zephyr/dts/xtensa/espressif/esp32s3/esp32s3_common.dtsi:366 */
			status = "disabled";                 /* in zephyr/dts/xtensa/espressif/esp32s3/esp32s3_common.dtsi:367 */
		};

		/* node '/soc/adc@60040000' defined in zephyr/dts/xtensa/espressif/esp32s3/esp32s3_common.dtsi:370 */
		adc0: adc@60040000 {
			compatible = "espressif,esp32-adc"; /* in zephyr/dts/xtensa/espressif/esp32s3/esp32s3_common.dtsi:371 */
			reg = < 0x60040000 0x4 >;           /* in zephyr/dts/xtensa/espressif/esp32s3/esp32s3_common.dtsi:372 */
			clocks = < &clock 0x80 >;           /* in zephyr/dts/xtensa/espressif/esp32s3/esp32s3_common.dtsi:373 */
			unit = < 0x1 >;                     /* in zephyr/dts/xtensa/espressif/esp32s3/esp32s3_common.dtsi:374 */
			channel-count = < 0xa >;            /* in zephyr/dts/xtensa/espressif/esp32s3/esp32s3_common.dtsi:375 */
			#io-channel-cells = < 0x1 >;        /* in zephyr/dts/xtensa/espressif/esp32s3/esp32s3_common.dtsi:376 */
			status = "okay";                    /* in iot_interactive_kit/boards/esp32s3_devkitc_esp32s3_procpu.overlay:110 */
			#address-cells = < 0x1 >;           /* in iot_interactive_kit/boards/esp32s3_devkitc_esp32s3_procpu.overlay:111 */
			#size-cells = < 0x0 >;              /* in iot_interactive_kit/boards/esp32s3_devkitc_esp32s3_procpu.overlay:112 */
			phandle = < 0x12 >;                 /* in iot_interactive_kit/boards/esp32s3_devkitc_esp32s3_procpu.overlay:51 */

			/* node '/soc/adc@60040000/channel@8' defined in iot_interactive_kit/boards/esp32s3_devkitc_esp32s3_procpu.overlay:115 */
			channel@8 {
				reg = < 0x8 >;                         /* in iot_interactive_kit/boards/esp32s3_devkitc_esp32s3_procpu.overlay:116 */
				zephyr,gain = "ADC_GAIN_1_4";          /* in iot_interactive_kit/boards/esp32s3_devkitc_esp32s3_procpu.overlay:117 */
				zephyr,reference = "ADC_REF_INTERNAL"; /* in iot_interactive_kit/boards/esp32s3_devkitc_esp32s3_procpu.overlay:118 */
				zephyr,acquisition-time = < 0x0 >;     /* in iot_interactive_kit/boards/esp32s3_devkitc_esp32s3_procpu.overlay:119 */
				zephyr,resolution = < 0xc >;           /* in iot_interactive_kit/boards/esp32s3_devkitc_esp32s3_procpu.overlay:120 */
			};

			/* node '/soc/adc@60040000/channel@9' defined in iot_interactive_kit/boards/esp32s3_devkitc_esp32s3_procpu.overlay:124 */
			channel@9 {
				reg = < 0x9 >;                         /* in iot_interactive_kit/boards/esp32s3_devkitc_esp32s3_procpu.overlay:125 */
				zephyr,gain = "ADC_GAIN_1_4";          /* in iot_interactive_kit/boards/esp32s3_devkitc_esp32s3_procpu.overlay:126 */
				zephyr,reference = "ADC_REF_INTERNAL"; /* in iot_interactive_kit/boards/esp32s3_devkitc_esp32s3_procpu.overlay:127 */
				zephyr,acquisition-time = < 0x0 >;     /* in iot_interactive_kit/boards/esp32s3_devkitc_esp32s3_procpu.overlay:128 */
				zephyr,resolution = < 0xc >;           /* in iot_interactive_kit/boards/esp32s3_devkitc_esp32s3_procpu.overlay:129 */
			};
		};

		/* node '/soc/adc@60040004' defined in zephyr/dts/xtensa/espressif/esp32s3/esp32s3_common.dtsi:380 */
		adc1: adc@60040004 {
			compatible = "espressif,esp32-adc"; /* in zephyr/dts/xtensa/espressif/esp32s3/esp32s3_common.dtsi:381 */
			reg = < 0x60040004 0x4 >;           /* in zephyr/dts/xtensa/espressif/esp32s3/esp32s3_common.dtsi:382 */
			clocks = < &clock 0x80 >;           /* in zephyr/dts/xtensa/espressif/esp32s3/esp32s3_common.dtsi:383 */
			unit = < 0x2 >;                     /* in zephyr/dts/xtensa/espressif/esp32s3/esp32s3_common.dtsi:384 */
			channel-count = < 0xa >;            /* in zephyr/dts/xtensa/espressif/esp32s3/esp32s3_common.dtsi:385 */
			#io-channel-cells = < 0x1 >;        /* in zephyr/dts/xtensa/espressif/esp32s3/esp32s3_common.dtsi:386 */
			status = "disabled";                /* in zephyr/dts/xtensa/espressif/esp32s3/esp32s3_common.dtsi:387 */
		};

		/* node '/soc/can@6002b000' defined in zephyr/dts/xtensa/espressif/esp32s3/esp32s3_common.dtsi:390 */
		twai: can@6002b000 {
			compatible = "espressif,esp32-twai"; /* in zephyr/dts/xtensa/espressif/esp32s3/esp32s3_common.dtsi:391 */
			reg = < 0x6002b000 0x1000 >;         /* in zephyr/dts/xtensa/espressif/esp32s3/esp32s3_common.dtsi:392 */
			interrupts = < 0x25 0x0 0x0 >;       /* in zephyr/dts/xtensa/espressif/esp32s3/esp32s3_common.dtsi:393 */
			interrupt-parent = < &intc >;        /* in zephyr/dts/xtensa/espressif/esp32s3/esp32s3_common.dtsi:394 */
			clocks = < &clock 0x76 >;            /* in zephyr/dts/xtensa/espressif/esp32s3/esp32s3_common.dtsi:395 */
			status = "disabled";                 /* in zephyr/dts/xtensa/espressif/esp32s3/esp32s3_common.dtsi:396 */
			pinctrl-0 = < &twai_default >;       /* in zephyr/boards/espressif/esp32s3_devkitc/esp32s3_devkitc_procpu.dts:115 */
			pinctrl-names = "default";           /* in zephyr/boards/espressif/esp32s3_devkitc/esp32s3_devkitc_procpu.dts:116 */
		};

		/* node '/soc/lcd_cam@60041000' defined in zephyr/dts/xtensa/espressif/esp32s3/esp32s3_common.dtsi:399 */
		lcd_cam: lcd_cam@60041000 {
			compatible = "espressif,esp32-lcd-cam"; /* in zephyr/dts/xtensa/espressif/esp32s3/esp32s3_common.dtsi:400 */
			reg = < 0x60041000 0x1000 >;            /* in zephyr/dts/xtensa/espressif/esp32s3/esp32s3_common.dtsi:401 */
			clocks = < &clock 0x2 >;                /* in zephyr/dts/xtensa/espressif/esp32s3/esp32s3_common.dtsi:402 */
			interrupts = < 0x18 0x0 0x0 >;          /* in zephyr/dts/xtensa/espressif/esp32s3/esp32s3_common.dtsi:403 */
			interrupt-parent = < &intc >;           /* in zephyr/dts/xtensa/espressif/esp32s3/esp32s3_common.dtsi:404 */
			dmas = < &dma 0x6 >,
			       < &dma 0x7 >;                    /* in zephyr/dts/xtensa/espressif/esp32s3/esp32s3_common.dtsi:405 */
			dma-names = "rx",
			            "tx";                       /* in zephyr/dts/xtensa/espressif/esp32s3/esp32s3_common.dtsi:406 */

			/* node '/soc/lcd_cam@60041000/lcd_cam_dvp' defined in zephyr/dts/xtensa/espressif/esp32s3/esp32s3_common.dtsi:408 */
			lcd_cam_dvp: lcd_cam_dvp {
				compatible = "espressif,esp32-lcd-cam-dvp"; /* in zephyr/dts/xtensa/espressif/esp32s3/esp32s3_common.dtsi:409 */
				status = "disabled";                        /* in zephyr/dts/xtensa/espressif/esp32s3/esp32s3_common.dtsi:410 */
			};

			/* node '/soc/lcd_cam@60041000/lcd_cam_disp' defined in zephyr/dts/xtensa/espressif/esp32s3/esp32s3_common.dtsi:413 */
			lcd_cam_disp: lcd_cam_disp {
				compatible = "espressif,esp32-lcd-cam-mipi-dbi"; /* in zephyr/dts/xtensa/espressif/esp32s3/esp32s3_common.dtsi:414 */
				#address-cells = < 0x1 >;                        /* in zephyr/dts/xtensa/espressif/esp32s3/esp32s3_common.dtsi:415 */
				#size-cells = < 0x0 >;                           /* in zephyr/dts/xtensa/espressif/esp32s3/esp32s3_common.dtsi:416 */
				status = "disabled";                             /* in zephyr/dts/xtensa/espressif/esp32s3/esp32s3_common.dtsi:417 */
			};
		};

		/* node '/soc/uart@60038000' defined in zephyr/dts/xtensa/espressif/esp32s3/esp32s3_common.dtsi:421 */
		usb_serial: uart@60038000 {
			compatible = "espressif,esp32-usb-serial"; /* in zephyr/dts/xtensa/espressif/esp32s3/esp32s3_common.dtsi:422 */
			reg = < 0x60038000 0x1000 >;               /* in zephyr/dts/xtensa/espressif/esp32s3/esp32s3_common.dtsi:423 */
			interrupts = < 0x60 0x0 0x0 >;             /* in zephyr/dts/xtensa/espressif/esp32s3/esp32s3_common.dtsi:425 */
			interrupt-parent = < &intc >;              /* in zephyr/dts/xtensa/espressif/esp32s3/esp32s3_common.dtsi:426 */
			clocks = < &clock 0x66 >;                  /* in zephyr/dts/xtensa/espressif/esp32s3/esp32s3_common.dtsi:427 */
			status = "disabled";                       /* in zephyr/boards/espressif/esp32s3_devkitc/esp32s3_devkitc_procpu.dts:46 */
		};

		/* node '/soc/usb_otg@60080000' defined in zephyr/dts/xtensa/espressif/esp32s3/esp32s3_common.dtsi:430 */
		usb_otg: zephyr_udc0: usb_otg@60080000 {
			compatible = "espressif,esp32-usb-otg",
			             "snps,dwc2";               /* in zephyr/dts/xtensa/espressif/esp32s3/esp32s3_common.dtsi:431 */
			reg = < 0x60080000 0x40000 >;           /* in zephyr/dts/xtensa/espressif/esp32s3/esp32s3_common.dtsi:432 */
			interrupts = < 0x26 0x0 0x0 >;          /* in zephyr/dts/xtensa/espressif/esp32s3/esp32s3_common.dtsi:434 */
			interrupt-parent = < &intc >;           /* in zephyr/dts/xtensa/espressif/esp32s3/esp32s3_common.dtsi:435 */
			clocks = < &clock 0x66 >;               /* in zephyr/dts/xtensa/espressif/esp32s3/esp32s3_common.dtsi:436 */
			num-out-eps = < 0x6 >;                  /* in zephyr/dts/xtensa/espressif/esp32s3/esp32s3_common.dtsi:437 */
			num-in-eps = < 0x6 >;                   /* in zephyr/dts/xtensa/espressif/esp32s3/esp32s3_common.dtsi:438 */
			ghwcfg1 = < 0x0 >;                      /* in zephyr/dts/xtensa/espressif/esp32s3/esp32s3_common.dtsi:439 */
			ghwcfg2 = < 0x224dd930 >;               /* in zephyr/dts/xtensa/espressif/esp32s3/esp32s3_common.dtsi:440 */
			ghwcfg4 = < 0xd3f0a030 >;               /* in zephyr/dts/xtensa/espressif/esp32s3/esp32s3_common.dtsi:441 */
			status = "okay";                        /* in zephyr/boards/espressif/esp32s3_devkitc/esp32s3_devkitc_procpu.dts:152 */
		};

		/* node '/soc/counter@6001f000' defined in zephyr/dts/xtensa/espressif/esp32s3/esp32s3_common.dtsi:444 */
		timer0: counter@6001f000 {
			compatible = "espressif,esp32-timer"; /* in zephyr/dts/xtensa/espressif/esp32s3/esp32s3_common.dtsi:445 */
			reg = < 0x6001f000 0x1000 >;          /* in zephyr/dts/xtensa/espressif/esp32s3/esp32s3_common.dtsi:446 */
			clocks = < &clock 0x3 >;              /* in zephyr/dts/xtensa/espressif/esp32s3/esp32s3_common.dtsi:447 */
			group = < 0x0 >;                      /* in zephyr/dts/xtensa/espressif/esp32s3/esp32s3_common.dtsi:448 */
			index = < 0x0 >;                      /* in zephyr/dts/xtensa/espressif/esp32s3/esp32s3_common.dtsi:449 */
			interrupts = < 0x32 0x0 0x0 >;        /* in zephyr/dts/xtensa/espressif/esp32s3/esp32s3_common.dtsi:450 */
			interrupt-parent = < &intc >;         /* in zephyr/dts/xtensa/espressif/esp32s3/esp32s3_common.dtsi:451 */
			status = "disabled";                  /* in zephyr/boards/espressif/esp32s3_devkitc/esp32s3_devkitc_procpu.dts:120 */

			/* node '/soc/counter@6001f000/counter' defined in zephyr/dts/xtensa/espressif/esp32s3/esp32s3_common.dtsi:454 */
			counter {
				compatible = "espressif,esp32-counter"; /* in zephyr/dts/xtensa/espressif/esp32s3/esp32s3_common.dtsi:455 */
				status = "disabled";                    /* in zephyr/dts/xtensa/espressif/esp32s3/esp32s3_common.dtsi:456 */
			};
		};

		/* node '/soc/counter@6001f024' defined in zephyr/dts/xtensa/espressif/esp32s3/esp32s3_common.dtsi:460 */
		timer1: counter@6001f024 {
			compatible = "espressif,esp32-timer"; /* in zephyr/dts/xtensa/espressif/esp32s3/esp32s3_common.dtsi:461 */
			reg = < 0x6001f024 0x1000 >;          /* in zephyr/dts/xtensa/espressif/esp32s3/esp32s3_common.dtsi:462 */
			clocks = < &clock 0x3 >;              /* in zephyr/dts/xtensa/espressif/esp32s3/esp32s3_common.dtsi:463 */
			group = < 0x0 >;                      /* in zephyr/dts/xtensa/espressif/esp32s3/esp32s3_common.dtsi:464 */
			index = < 0x1 >;                      /* in zephyr/dts/xtensa/espressif/esp32s3/esp32s3_common.dtsi:465 */
			interrupts = < 0x33 0x0 0x0 >;        /* in zephyr/dts/xtensa/espressif/esp32s3/esp32s3_common.dtsi:466 */
			interrupt-parent = < &intc >;         /* in zephyr/dts/xtensa/espressif/esp32s3/esp32s3_common.dtsi:467 */
			status = "disabled";                  /* in zephyr/boards/espressif/esp32s3_devkitc/esp32s3_devkitc_procpu.dts:124 */

			/* node '/soc/counter@6001f024/counter' defined in zephyr/dts/xtensa/espressif/esp32s3/esp32s3_common.dtsi:470 */
			counter {
				compatible = "espressif,esp32-counter"; /* in zephyr/dts/xtensa/espressif/esp32s3/esp32s3_common.dtsi:471 */
				status = "disabled";                    /* in zephyr/dts/xtensa/espressif/esp32s3/esp32s3_common.dtsi:472 */
			};
		};

		/* node '/soc/counter@60020000' defined in zephyr/dts/xtensa/espressif/esp32s3/esp32s3_common.dtsi:476 */
		timer2: counter@60020000 {
			compatible = "espressif,esp32-timer"; /* in zephyr/dts/xtensa/espressif/esp32s3/esp32s3_common.dtsi:477 */
			reg = < 0x60020000 0x1000 >;          /* in zephyr/dts/xtensa/espressif/esp32s3/esp32s3_common.dtsi:478 */
			clocks = < &clock 0x4 >;              /* in zephyr/dts/xtensa/espressif/esp32s3/esp32s3_common.dtsi:479 */
			group = < 0x1 >;                      /* in zephyr/dts/xtensa/espressif/esp32s3/esp32s3_common.dtsi:480 */
			index = < 0x0 >;                      /* in zephyr/dts/xtensa/espressif/esp32s3/esp32s3_common.dtsi:481 */
			interrupts = < 0x35 0x0 0x0 >;        /* in zephyr/dts/xtensa/espressif/esp32s3/esp32s3_common.dtsi:482 */
			interrupt-parent = < &intc >;         /* in zephyr/dts/xtensa/espressif/esp32s3/esp32s3_common.dtsi:483 */
			status = "disabled";                  /* in zephyr/boards/espressif/esp32s3_devkitc/esp32s3_devkitc_procpu.dts:128 */

			/* node '/soc/counter@60020000/counter' defined in zephyr/dts/xtensa/espressif/esp32s3/esp32s3_common.dtsi:486 */
			counter {
				compatible = "espressif,esp32-counter"; /* in zephyr/dts/xtensa/espressif/esp32s3/esp32s3_common.dtsi:487 */
				status = "disabled";                    /* in zephyr/dts/xtensa/espressif/esp32s3/esp32s3_common.dtsi:488 */
			};
		};

		/* node '/soc/counter@60020024' defined in zephyr/dts/xtensa/espressif/esp32s3/esp32s3_common.dtsi:492 */
		timer3: counter@60020024 {
			compatible = "espressif,esp32-timer"; /* in zephyr/dts/xtensa/espressif/esp32s3/esp32s3_common.dtsi:493 */
			reg = < 0x60020024 0x1000 >;          /* in zephyr/dts/xtensa/espressif/esp32s3/esp32s3_common.dtsi:494 */
			clocks = < &clock 0x4 >;              /* in zephyr/dts/xtensa/espressif/esp32s3/esp32s3_common.dtsi:495 */
			group = < 0x1 >;                      /* in zephyr/dts/xtensa/espressif/esp32s3/esp32s3_common.dtsi:496 */
			index = < 0x1 >;                      /* in zephyr/dts/xtensa/espressif/esp32s3/esp32s3_common.dtsi:497 */
			interrupts = < 0x36 0x0 0x0 >;        /* in zephyr/dts/xtensa/espressif/esp32s3/esp32s3_common.dtsi:498 */
			interrupt-parent = < &intc >;         /* in zephyr/dts/xtensa/espressif/esp32s3/esp32s3_common.dtsi:499 */
			status = "disabled";                  /* in zephyr/boards/espressif/esp32s3_devkitc/esp32s3_devkitc_procpu.dts:132 */

			/* node '/soc/counter@60020024/counter' defined in zephyr/dts/xtensa/espressif/esp32s3/esp32s3_common.dtsi:501 */
			counter {
				compatible = "espressif,esp32-counter"; /* in zephyr/dts/xtensa/espressif/esp32s3/esp32s3_common.dtsi:502 */
				status = "disabled";                    /* in zephyr/dts/xtensa/espressif/esp32s3/esp32s3_common.dtsi:503 */
			};
		};

		/* node '/soc/watchdog@6001f048' defined in zephyr/dts/xtensa/espressif/esp32s3/esp32s3_common.dtsi:507 */
		wdt0: watchdog@6001f048 {
			compatible = "espressif,esp32-watchdog"; /* in zephyr/dts/xtensa/espressif/esp32s3/esp32s3_common.dtsi:508 */
			reg = < 0x6001f048 0x20 >;               /* in zephyr/dts/xtensa/espressif/esp32s3/esp32s3_common.dtsi:509 */
			interrupts = < 0x34 0x0 0x0 >;           /* in zephyr/dts/xtensa/espressif/esp32s3/esp32s3_common.dtsi:510 */
			interrupt-parent = < &intc >;            /* in zephyr/dts/xtensa/espressif/esp32s3/esp32s3_common.dtsi:511 */
			clocks = < &clock 0x3 >;                 /* in zephyr/dts/xtensa/espressif/esp32s3/esp32s3_common.dtsi:512 */
			status = "okay";                         /* in zephyr/boards/espressif/esp32s3_devkitc/esp32s3_devkitc_procpu.dts:136 */
		};

		/* node '/soc/watchdog@60020048' defined in zephyr/dts/xtensa/espressif/esp32s3/esp32s3_common.dtsi:516 */
		wdt1: watchdog@60020048 {
			compatible = "espressif,esp32-watchdog"; /* in zephyr/dts/xtensa/espressif/esp32s3/esp32s3_common.dtsi:517 */
			reg = < 0x60020048 0x20 >;               /* in zephyr/dts/xtensa/espressif/esp32s3/esp32s3_common.dtsi:518 */
			interrupts = < 0x37 0x0 0x0 >;           /* in zephyr/dts/xtensa/espressif/esp32s3/esp32s3_common.dtsi:519 */
			interrupt-parent = < &intc >;            /* in zephyr/dts/xtensa/espressif/esp32s3/esp32s3_common.dtsi:520 */
			clocks = < &clock 0x4 >;                 /* in zephyr/dts/xtensa/espressif/esp32s3/esp32s3_common.dtsi:521 */
			status = "disabled";                     /* in zephyr/dts/xtensa/espressif/esp32s3/esp32s3_common.dtsi:522 */
		};

		/* node '/soc/trng@6003507c' defined in zephyr/dts/xtensa/espressif/esp32s3/esp32s3_common.dtsi:525 */
		trng0: trng@6003507c {
			compatible = "espressif,esp32-trng"; /* in zephyr/dts/xtensa/espressif/esp32s3/esp32s3_common.dtsi:526 */
			reg = < 0x6003507c 0x4 >;            /* in zephyr/dts/xtensa/espressif/esp32s3/esp32s3_common.dtsi:527 */
			clocks = < &clock 0x6 >;             /* in zephyr/dts/xtensa/espressif/esp32s3/esp32s3_common.dtsi:528 */
			status = "okay";                     /* in zephyr/boards/espressif/esp32s3_devkitc/esp32s3_devkitc_procpu.dts:140 */
		};

		/* node '/soc/ledc@60019000' defined in zephyr/dts/xtensa/espressif/esp32s3/esp32s3_common.dtsi:532 */
		ledc0: ledc@60019000 {
			compatible = "espressif,esp32-ledc"; /* in zephyr/dts/xtensa/espressif/esp32s3/esp32s3_common.dtsi:533 */
			#pwm-cells = < 0x3 >;                /* in zephyr/dts/xtensa/espressif/esp32s3/esp32s3_common.dtsi:534 */
			reg = < 0x60019000 0x1000 >;         /* in zephyr/dts/xtensa/espressif/esp32s3/esp32s3_common.dtsi:535 */
			clocks = < &clock 0x64 >;            /* in zephyr/dts/xtensa/espressif/esp32s3/esp32s3_common.dtsi:536 */
			pinctrl-0 = < &ledc0_default >;      /* in iot_interactive_kit/boards/esp32s3_devkitc_esp32s3_procpu.overlay:148 */
			pinctrl-names = "default";           /* in iot_interactive_kit/boards/esp32s3_devkitc_esp32s3_procpu.overlay:149 */
			status = "okay";                     /* in iot_interactive_kit/boards/esp32s3_devkitc_esp32s3_procpu.overlay:150 */
			#address-cells = < 0x1 >;            /* in iot_interactive_kit/boards/esp32s3_devkitc_esp32s3_procpu.overlay:151 */
			#size-cells = < 0x0 >;               /* in iot_interactive_kit/boards/esp32s3_devkitc_esp32s3_procpu.overlay:152 */

			/* node '/soc/ledc@60019000/channel0@0' defined in iot_interactive_kit/boards/esp32s3_devkitc_esp32s3_procpu.overlay:154 */
			channel0@0 {
				reg = < 0x0 >;   /* in iot_interactive_kit/boards/esp32s3_devkitc_esp32s3_procpu.overlay:155 */
				timer = < 0x0 >; /* in iot_interactive_kit/boards/esp32s3_devkitc_esp32s3_procpu.overlay:156 */
			};

			/* node '/soc/ledc@60019000/channel1@1' defined in iot_interactive_kit/boards/esp32s3_devkitc_esp32s3_procpu.overlay:159 */
			channel1@1 {
				reg = < 0x1 >;   /* in iot_interactive_kit/boards/esp32s3_devkitc_esp32s3_procpu.overlay:160 */
				timer = < 0x1 >; /* in iot_interactive_kit/boards/esp32s3_devkitc_esp32s3_procpu.overlay:161 */
			};

			/* node '/soc/ledc@60019000/channel3@3' defined in iot_interactive_kit/boards/esp32s3_devkitc_esp32s3_procpu.overlay:164 */
			channel3@3 {
				reg = < 0x3 >;   /* in iot_interactive_kit/boards/esp32s3_devkitc_esp32s3_procpu.overlay:165 */
				timer = < 0x2 >; /* in iot_interactive_kit/boards/esp32s3_devkitc_esp32s3_procpu.overlay:166 */
			};

			/* node '/soc/ledc@60019000/channel4@4' defined in iot_interactive_kit/boards/esp32s3_devkitc_esp32s3_procpu.overlay:169 */
			channel4@4 {
				reg = < 0x4 >;   /* in iot_interactive_kit/boards/esp32s3_devkitc_esp32s3_procpu.overlay:170 */
				timer = < 0x3 >; /* in iot_interactive_kit/boards/esp32s3_devkitc_esp32s3_procpu.overlay:171 */
			};
		};

		/* node '/soc/mcpwm@6001e000' defined in zephyr/dts/xtensa/espressif/esp32s3/esp32s3_common.dtsi:540 */
		mcpwm0: mcpwm@6001e000 {
			compatible = "espressif,esp32-mcpwm"; /* in zephyr/dts/xtensa/espressif/esp32s3/esp32s3_common.dtsi:541 */
			reg = < 0x6001e000 0x1000 >;          /* in zephyr/dts/xtensa/espressif/esp32s3/esp32s3_common.dtsi:542 */
			interrupts = < 0x1f 0x0 0x0 >;        /* in zephyr/dts/xtensa/espressif/esp32s3/esp32s3_common.dtsi:543 */
			interrupt-parent = < &intc >;         /* in zephyr/dts/xtensa/espressif/esp32s3/esp32s3_common.dtsi:544 */
			clocks = < &clock 0x6b >;             /* in zephyr/dts/xtensa/espressif/esp32s3/esp32s3_common.dtsi:545 */
			#pwm-cells = < 0x3 >;                 /* in zephyr/dts/xtensa/espressif/esp32s3/esp32s3_common.dtsi:546 */
			status = "disabled";                  /* in zephyr/dts/xtensa/espressif/esp32s3/esp32s3_common.dtsi:547 */
		};

		/* node '/soc/mcpwm@6002c000' defined in zephyr/dts/xtensa/espressif/esp32s3/esp32s3_common.dtsi:550 */
		mcpwm1: mcpwm@6002c000 {
			compatible = "espressif,esp32-mcpwm"; /* in zephyr/dts/xtensa/espressif/esp32s3/esp32s3_common.dtsi:551 */
			reg = < 0x6002c000 0x1000 >;          /* in zephyr/dts/xtensa/espressif/esp32s3/esp32s3_common.dtsi:552 */
			interrupts = < 0x20 0x0 0x0 >;        /* in zephyr/dts/xtensa/espressif/esp32s3/esp32s3_common.dtsi:553 */
			interrupt-parent = < &intc >;         /* in zephyr/dts/xtensa/espressif/esp32s3/esp32s3_common.dtsi:554 */
			clocks = < &clock 0x6c >;             /* in zephyr/dts/xtensa/espressif/esp32s3/esp32s3_common.dtsi:555 */
			#pwm-cells = < 0x3 >;                 /* in zephyr/dts/xtensa/espressif/esp32s3/esp32s3_common.dtsi:556 */
			status = "disabled";                  /* in zephyr/dts/xtensa/espressif/esp32s3/esp32s3_common.dtsi:557 */
		};

		/* node '/soc/pcnt@60017000' defined in zephyr/dts/xtensa/espressif/esp32s3/esp32s3_common.dtsi:560 */
		pcnt: pcnt@60017000 {
			compatible = "espressif,esp32-pcnt"; /* in zephyr/dts/xtensa/espressif/esp32s3/esp32s3_common.dtsi:561 */
			reg = < 0x60017000 0x1000 >;         /* in zephyr/dts/xtensa/espressif/esp32s3/esp32s3_common.dtsi:562 */
			interrupts = < 0x29 0x0 0x0 >;       /* in zephyr/dts/xtensa/espressif/esp32s3/esp32s3_common.dtsi:563 */
			interrupt-parent = < &intc >;        /* in zephyr/dts/xtensa/espressif/esp32s3/esp32s3_common.dtsi:564 */
			clocks = < &clock 0x71 >;            /* in zephyr/dts/xtensa/espressif/esp32s3/esp32s3_common.dtsi:565 */
			status = "disabled";                 /* in zephyr/dts/xtensa/espressif/esp32s3/esp32s3_common.dtsi:566 */
		};

		/* node '/soc/dma@6003f000' defined in zephyr/dts/xtensa/espressif/esp32s3/esp32s3_common.dtsi:569 */
		dma: dma@6003f000 {
			compatible = "espressif,esp32-gdma"; /* in zephyr/dts/xtensa/espressif/esp32s3/esp32s3_common.dtsi:570 */
			reg = < 0x6003f000 0x1000 >;         /* in zephyr/dts/xtensa/espressif/esp32s3/esp32s3_common.dtsi:571 */
			#dma-cells = < 0x1 >;                /* in zephyr/dts/xtensa/espressif/esp32s3/esp32s3_common.dtsi:572 */
			interrupts = < 0x42 0x0 0x100 >,
			             < 0x47 0x0 0x100 >,
			             < 0x43 0x0 0x100 >,
			             < 0x48 0x0 0x100 >,
			             < 0x44 0x0 0x100 >,
			             < 0x49 0x0 0x100 >,
			             < 0x45 0x0 0x100 >,
			             < 0x4a 0x0 0x100 >,
			             < 0x46 0x0 0x100 >,
			             < 0x4b 0x0 0x100 >;     /* in zephyr/dts/xtensa/espressif/esp32s3/esp32s3_common.dtsi:573 */
			interrupt-parent = < &intc >;        /* in zephyr/dts/xtensa/espressif/esp32s3/esp32s3_common.dtsi:593 */
			clocks = < &clock 0x7e >;            /* in zephyr/dts/xtensa/espressif/esp32s3/esp32s3_common.dtsi:594 */
			dma-channels = < 0xa >;              /* in zephyr/dts/xtensa/espressif/esp32s3/esp32s3_common.dtsi:595 */
			dma-buf-addr-alignment = < 0x4 >;    /* in zephyr/dts/xtensa/espressif/esp32s3/esp32s3_common.dtsi:596 */
			status = "okay";                     /* in iot_interactive_kit/boards/esp32s3_devkitc_esp32s3_procpu.overlay:94 */
			phandle = < 0xa >;                   /* in iot_interactive_kit/boards/esp32s3_devkitc_esp32s3_procpu.overlay:78 */
		};

		/* node '/soc/sdhc@60028000' defined in zephyr/dts/xtensa/espressif/esp32s3/esp32s3_common.dtsi:600 */
		sdhc: sdhc@60028000 {
			compatible = "espressif,esp32-sdhc"; /* in zephyr/dts/xtensa/espressif/esp32s3/esp32s3_common.dtsi:601 */
			reg = < 0x60028000 0x1000 >;         /* in zephyr/dts/xtensa/espressif/esp32s3/esp32s3_common.dtsi:602 */
			interrupts = < 0x1e 0x0 0x0 >;       /* in zephyr/dts/xtensa/espressif/esp32s3/esp32s3_common.dtsi:603 */
			interrupt-parent = < &intc >;        /* in zephyr/dts/xtensa/espressif/esp32s3/esp32s3_common.dtsi:604 */
			clocks = < &clock 0x75 >;            /* in zephyr/dts/xtensa/espressif/esp32s3/esp32s3_common.dtsi:605 */
			#address-cells = < 0x1 >;            /* in zephyr/dts/xtensa/espressif/esp32s3/esp32s3_common.dtsi:606 */
			#size-cells = < 0x0 >;               /* in zephyr/dts/xtensa/espressif/esp32s3/esp32s3_common.dtsi:607 */

			/* node '/soc/sdhc@60028000/sdhc@0' defined in zephyr/dts/xtensa/espressif/esp32s3/esp32s3_common.dtsi:609 */
			sdhc0: sdhc@0 {
				compatible = "espressif,esp32-sdhc-slot"; /* in zephyr/dts/xtensa/espressif/esp32s3/esp32s3_common.dtsi:610 */
				reg = < 0x0 >;                            /* in zephyr/dts/xtensa/espressif/esp32s3/esp32s3_common.dtsi:611 */
				status = "disabled";                      /* in zephyr/dts/xtensa/espressif/esp32s3/esp32s3_common.dtsi:612 */
			};

			/* node '/soc/sdhc@60028000/sdhc@1' defined in zephyr/dts/xtensa/espressif/esp32s3/esp32s3_common.dtsi:615 */
			sdhc1: sdhc@1 {
				compatible = "espressif,esp32-sdhc-slot"; /* in zephyr/dts/xtensa/espressif/esp32s3/esp32s3_common.dtsi:616 */
				reg = < 0x1 >;                            /* in zephyr/dts/xtensa/espressif/esp32s3/esp32s3_common.dtsi:617 */
				status = "disabled";                      /* in zephyr/dts/xtensa/espressif/esp32s3/esp32s3_common.dtsi:618 */
			};
		};

		/* node '/soc/sha@6003b000' defined in zephyr/dts/xtensa/espressif/esp32s3/esp32s3_common.dtsi:622 */
		sha: sha@6003b000 {
			compatible = "espressif,esp32-sha"; /* in zephyr/dts/xtensa/espressif/esp32s3/esp32s3_common.dtsi:623 */
			reg = < 0x6003b000 0x100 >;         /* in zephyr/dts/xtensa/espressif/esp32s3/esp32s3_common.dtsi:624 */
			clocks = < &clock 0x7a >;           /* in zephyr/dts/xtensa/espressif/esp32s3/esp32s3_common.dtsi:625 */
			status = "okay";                    /* in zephyr/dts/xtensa/espressif/esp32s3/esp32s3_common.dtsi:626 */
		};

		/* node '/soc/aes@6003a000' defined in zephyr/dts/xtensa/espressif/esp32s3/esp32s3_common.dtsi:629 */
		aes: aes@6003a000 {
			compatible = "espressif,esp32-aes"; /* in zephyr/dts/xtensa/espressif/esp32s3/esp32s3_common.dtsi:630 */
			reg = < 0x6003a000 0x1000 >;        /* in zephyr/dts/xtensa/espressif/esp32s3/esp32s3_common.dtsi:631 */
			clocks = < &clock 0x79 >;           /* in zephyr/dts/xtensa/espressif/esp32s3/esp32s3_common.dtsi:632 */
			status = "okay";                    /* in zephyr/dts/xtensa/espressif/esp32s3/esp32s3_common.dtsi:633 */
		};
	};

	/* node '/cpus' defined in zephyr/dts/xtensa/espressif/esp32s3/esp32s3_common.dtsi:28 */
	cpus {
		#address-cells = < 0x1 >; /* in zephyr/dts/xtensa/espressif/esp32s3/esp32s3_common.dtsi:29 */
		#size-cells = < 0x0 >;    /* in zephyr/dts/xtensa/espressif/esp32s3/esp32s3_common.dtsi:30 */

		/* node '/cpus/cpu@0' defined in zephyr/dts/xtensa/espressif/esp32s3/esp32s3_common.dtsi:32 */
		cpu0: cpu@0 {
			device_type = "cpu";                             /* in zephyr/dts/xtensa/espressif/esp32s3/esp32s3_common.dtsi:33 */
			compatible = "espressif,xtensa-lx7";             /* in zephyr/dts/xtensa/espressif/esp32s3/esp32s3_common.dtsi:34 */
			reg = < 0x0 >;                                   /* in zephyr/dts/xtensa/espressif/esp32s3/esp32s3_common.dtsi:35 */
			cpu-power-states = < &light_sleep &deep_sleep >; /* in zephyr/dts/xtensa/espressif/esp32s3/esp32s3_common.dtsi:36 */
			clock-source = < 0x1 >;                          /* in zephyr/dts/xtensa/espressif/esp32s3/esp32s3_common.dtsi:37 */
			clock-frequency = < 0xe4e1c00 >;                 /* in zephyr/dts/xtensa/espressif/esp32s3/esp32s3_common.dtsi:38 */
			xtal-freq = < 0x2625a00 >;                       /* in zephyr/dts/xtensa/espressif/esp32s3/esp32s3_common.dtsi:39 */
		};

		/* node '/cpus/cpu@1' defined in zephyr/dts/xtensa/espressif/esp32s3/esp32s3_common.dtsi:42 */
		cpu1: cpu@1 {
			device_type = "cpu";                 /* in zephyr/dts/xtensa/espressif/esp32s3/esp32s3_common.dtsi:43 */
			compatible = "espressif,xtensa-lx7"; /* in zephyr/dts/xtensa/espressif/esp32s3/esp32s3_common.dtsi:44 */
			reg = < 0x1 >;                       /* in zephyr/dts/xtensa/espressif/esp32s3/esp32s3_common.dtsi:45 */
			clock-source = < 0x1 >;              /* in zephyr/dts/xtensa/espressif/esp32s3/esp32s3_common.dtsi:46 */
			clock-frequency = < 0xe4e1c00 >;     /* in zephyr/dts/xtensa/espressif/esp32s3/esp32s3_common.dtsi:47 */
			xtal-freq = < 0x2625a00 >;           /* in zephyr/dts/xtensa/espressif/esp32s3/esp32s3_common.dtsi:48 */
		};

		/* node '/cpus/power-states' defined in zephyr/dts/xtensa/espressif/esp32s3/esp32s3_common.dtsi:51 */
		power-states {

			/* node '/cpus/power-states/light_sleep' defined in zephyr/dts/xtensa/espressif/esp32s3/esp32s3_common.dtsi:52 */
			light_sleep: light_sleep {
				compatible = "zephyr,power-state"; /* in zephyr/dts/xtensa/espressif/esp32s3/esp32s3_common.dtsi:53 */
				power-state-name = "standby";      /* in zephyr/dts/xtensa/espressif/esp32s3/esp32s3_common.dtsi:54 */
				min-residency-us = < 0x3e8 >;      /* in zephyr/dts/xtensa/espressif/esp32s3/esp32s3_common.dtsi:55 */
				exit-latency-us = < 0x32 >;        /* in zephyr/dts/xtensa/espressif/esp32s3/esp32s3_common.dtsi:56 */
				phandle = < 0x10 >;                /* in zephyr/dts/xtensa/espressif/esp32s3/esp32s3_common.dtsi:36 */
			};

			/* node '/cpus/power-states/deep_sleep' defined in zephyr/dts/xtensa/espressif/esp32s3/esp32s3_common.dtsi:59 */
			deep_sleep: deep_sleep {
				compatible = "zephyr,power-state"; /* in zephyr/dts/xtensa/espressif/esp32s3/esp32s3_common.dtsi:63 */
				power-state-name = "soft-off";     /* in zephyr/dts/xtensa/espressif/esp32s3/esp32s3_common.dtsi:64 */
				status = "disabled";               /* in zephyr/dts/xtensa/espressif/esp32s3/esp32s3_common.dtsi:65 */
				phandle = < 0x11 >;                /* in zephyr/dts/xtensa/espressif/esp32s3/esp32s3_common.dtsi:36 */
			};
		};
	};

	/* node '/wifi' defined in zephyr/dts/xtensa/espressif/esp32s3/esp32s3_common.dtsi:70 */
	wifi: wifi {
		compatible = "espressif,esp32-wifi"; /* in zephyr/dts/xtensa/espressif/esp32s3/esp32s3_common.dtsi:71 */
		status = "okay";                     /* in zephyr/boards/espressif/esp32s3_devkitc/esp32s3_devkitc_procpu.dts:148 */
	};

	/* node '/esp32_bt_hci' defined in zephyr/dts/xtensa/espressif/esp32s3/esp32s3_common.dtsi:75 */
	esp32_bt_hci: esp32_bt_hci {
		compatible = "espressif,esp32-bt-hci"; /* in zephyr/dts/xtensa/espressif/esp32s3/esp32s3_common.dtsi:76 */
		bt-hci-vs-ext;                         /* in zephyr/dts/xtensa/espressif/esp32s3/esp32s3_common.dtsi:77 */
		status = "okay";                       /* in zephyr/boards/espressif/esp32s3_devkitc/esp32s3_devkitc_procpu.dts:144 */
	};

	/* node '/pin-controller' defined in zephyr/dts/xtensa/espressif/esp32s3/esp32s3_common.dtsi:81 */
	pinctrl: pin-controller {
		compatible = "espressif,esp32-pinctrl"; /* in zephyr/dts/xtensa/espressif/esp32s3/esp32s3_common.dtsi:82 */
		status = "okay";                        /* in zephyr/dts/xtensa/espressif/esp32s3/esp32s3_common.dtsi:83 */

		/* node '/pin-controller/uart0_default' defined in zephyr/boards/espressif/esp32s3_devkitc/esp32s3_devkitc-pinctrl.dtsi:12 */
		uart0_default: uart0_default {
			phandle = < 0x4 >; /* in zephyr/boards/espressif/esp32s3_devkitc/esp32s3_devkitc_procpu.dts:52 */

			/* node '/pin-controller/uart0_default/group1' defined in zephyr/boards/espressif/esp32s3_devkitc/esp32s3_devkitc-pinctrl.dtsi:13 */
			group1 {
				pinmux = < 0x67feb >; /* in zephyr/boards/espressif/esp32s3_devkitc/esp32s3_devkitc-pinctrl.dtsi:14 */
				output-high;          /* in zephyr/boards/espressif/esp32s3_devkitc/esp32s3_devkitc-pinctrl.dtsi:15 */
			};

			/* node '/pin-controller/uart0_default/group2' defined in zephyr/boards/espressif/esp32s3_devkitc/esp32s3_devkitc-pinctrl.dtsi:18 */
			group2 {
				pinmux = < 0xff832c >; /* in zephyr/boards/espressif/esp32s3_devkitc/esp32s3_devkitc-pinctrl.dtsi:19 */
				bias-pull-up;          /* in zephyr/boards/espressif/esp32s3_devkitc/esp32s3_devkitc-pinctrl.dtsi:20 */
			};
		};

		/* node '/pin-controller/uart1_default' defined in zephyr/boards/espressif/esp32s3_devkitc/esp32s3_devkitc-pinctrl.dtsi:24 */
		uart1_default: uart1_default {

			/* node '/pin-controller/uart1_default/group1' defined in zephyr/boards/espressif/esp32s3_devkitc/esp32s3_devkitc-pinctrl.dtsi:25 */
			group1 {
				pinmux = < 0x7ffd1 >; /* in zephyr/boards/espressif/esp32s3_devkitc/esp32s3_devkitc-pinctrl.dtsi:26 */
				output-high;          /* in zephyr/boards/espressif/esp32s3_devkitc/esp32s3_devkitc-pinctrl.dtsi:27 */
			};

			/* node '/pin-controller/uart1_default/group2' defined in zephyr/boards/espressif/esp32s3_devkitc/esp32s3_devkitc-pinctrl.dtsi:30 */
			group2 {
				pinmux = < 0xff83d2 >; /* in zephyr/boards/espressif/esp32s3_devkitc/esp32s3_devkitc-pinctrl.dtsi:31 */
				bias-pull-up;          /* in zephyr/boards/espressif/esp32s3_devkitc/esp32s3_devkitc-pinctrl.dtsi:32 */
			};
		};

		/* node '/pin-controller/i2c0_default' defined in zephyr/boards/espressif/esp32s3_devkitc/esp32s3_devkitc-pinctrl.dtsi:36 */
		i2c0_default: i2c0_default {
			phandle = < 0x7 >; /* in iot_interactive_kit/boards/esp32s3_devkitc_esp32s3_procpu.overlay:136 */

			/* node '/pin-controller/i2c0_default/group1' defined in zephyr/boards/espressif/esp32s3_devkitc/esp32s3_devkitc-pinctrl.dtsi:37 */
			group1 {
				pinmux = < 0x2d1681 >,
				         < 0x2c9642 >; /* in zephyr/boards/espressif/esp32s3_devkitc/esp32s3_devkitc-pinctrl.dtsi:38 */
				bias-pull-up;          /* in zephyr/boards/espressif/esp32s3_devkitc/esp32s3_devkitc-pinctrl.dtsi:40 */
				drive-open-drain;      /* in zephyr/boards/espressif/esp32s3_devkitc/esp32s3_devkitc-pinctrl.dtsi:41 */
				output-high;           /* in zephyr/boards/espressif/esp32s3_devkitc/esp32s3_devkitc-pinctrl.dtsi:42 */
			};
		};

		/* node '/pin-controller/i2c1_default' defined in zephyr/boards/espressif/esp32s3_devkitc/esp32s3_devkitc-pinctrl.dtsi:46 */
		i2c1_default: i2c1_default {
			phandle = < 0x8 >; /* in zephyr/boards/espressif/esp32s3_devkitc/esp32s3_devkitc_procpu.dts:84 */

			/* node '/pin-controller/i2c1_default/group1' defined in zephyr/boards/espressif/esp32s3_devkitc/esp32s3_devkitc-pinctrl.dtsi:47 */
			group1 {
				pinmux = < 0x2e1704 >,
				         < 0x2d96c5 >; /* in zephyr/boards/espressif/esp32s3_devkitc/esp32s3_devkitc-pinctrl.dtsi:48 */
				bias-pull-up;          /* in zephyr/boards/espressif/esp32s3_devkitc/esp32s3_devkitc-pinctrl.dtsi:50 */
				drive-open-drain;      /* in zephyr/boards/espressif/esp32s3_devkitc/esp32s3_devkitc-pinctrl.dtsi:51 */
				output-high;           /* in zephyr/boards/espressif/esp32s3_devkitc/esp32s3_devkitc-pinctrl.dtsi:52 */
			};
		};

		/* node '/pin-controller/i2s0_default' defined in zephyr/boards/espressif/esp32s3_devkitc/esp32s3_devkitc-pinctrl.dtsi:56 */
		i2s0_default: i2s0_default {
			phandle = < 0x9 >; /* in zephyr/boards/espressif/esp32s3_devkitc/esp32s3_devkitc_procpu.dts:89 */

			/* node '/pin-controller/i2s0_default/group1' defined in zephyr/boards/espressif/esp32s3_devkitc/esp32s3_devkitc-pinctrl.dtsi:57 */
			group1 {
				pinmux = < 0xcfff0 >; /* in iot_interactive_kit/boards/esp32s3_devkitc_esp32s3_procpu.overlay:71 */
			};
		};

		/* node '/pin-controller/i2s1_default' defined in zephyr/boards/espressif/esp32s3_devkitc/esp32s3_devkitc-pinctrl.dtsi:66 */
		i2s1_default: i2s1_default {
			phandle = < 0xb >; /* in zephyr/boards/espressif/esp32s3_devkitc/esp32s3_devkitc_procpu.dts:94 */

			/* node '/pin-controller/i2s1_default/group1' defined in zephyr/boards/espressif/esp32s3_devkitc/esp32s3_devkitc-pinctrl.dtsi:67 */
			group1 {
				pinmux = < 0xafff0 >,
				         < 0xe8744 >,
				         < 0xe0705 >,
				         < 0xf7fc6 >,
				         < 0xff878c >; /* in zephyr/boards/espressif/esp32s3_devkitc/esp32s3_devkitc-pinctrl.dtsi:68 */
			};
		};

		/* node '/pin-controller/spim2_default' defined in zephyr/boards/espressif/esp32s3_devkitc/esp32s3_devkitc-pinctrl.dtsi:76 */
		spim2_default: spim2_default {
			phandle = < 0xc >; /* in zephyr/boards/espressif/esp32s3_devkitc/esp32s3_devkitc_procpu.dts:102 */

			/* node '/pin-controller/spim2_default/group1' defined in zephyr/boards/espressif/esp32s3_devkitc/esp32s3_devkitc-pinctrl.dtsi:77 */
			group1 {
				pinmux = < 0xff998d >,
				         < 0x32ffcc >,
				         < 0x377fca >; /* in zephyr/boards/espressif/esp32s3_devkitc/esp32s3_devkitc-pinctrl.dtsi:78 */
			};

			/* node '/pin-controller/spim2_default/group2' defined in zephyr/boards/espressif/esp32s3_devkitc/esp32s3_devkitc-pinctrl.dtsi:83 */
			group2 {
				pinmux = < 0x33ffcb >; /* in zephyr/boards/espressif/esp32s3_devkitc/esp32s3_devkitc-pinctrl.dtsi:84 */
				output-low;            /* in zephyr/boards/espressif/esp32s3_devkitc/esp32s3_devkitc-pinctrl.dtsi:85 */
			};
		};

		/* node '/pin-controller/spim3_default' defined in zephyr/boards/espressif/esp32s3_devkitc/esp32s3_devkitc-pinctrl.dtsi:89 */
		spim3_default: spim3_default {
			phandle = < 0xd >; /* in zephyr/boards/espressif/esp32s3_devkitc/esp32s3_devkitc_procpu.dts:110 */

			/* node '/pin-controller/spim3_default/group1' defined in zephyr/boards/espressif/esp32s3_devkitc/esp32s3_devkitc-pinctrl.dtsi:90 */
			group1 {
				pinmux = < 0xff90e5 >,
				         < 0x217fe4 >,
				         < 0x23ffe6 >; /* in zephyr/boards/espressif/esp32s3_devkitc/esp32s3_devkitc-pinctrl.dtsi:91 */
			};

			/* node '/pin-controller/spim3_default/group2' defined in zephyr/boards/espressif/esp32s3_devkitc/esp32s3_devkitc-pinctrl.dtsi:96 */
			group2 {
				pinmux = < 0x227fe7 >; /* in zephyr/boards/espressif/esp32s3_devkitc/esp32s3_devkitc-pinctrl.dtsi:97 */
				output-low;            /* in zephyr/boards/espressif/esp32s3_devkitc/esp32s3_devkitc-pinctrl.dtsi:98 */
			};
		};

		/* node '/pin-controller/twai_default' defined in zephyr/boards/espressif/esp32s3_devkitc/esp32s3_devkitc-pinctrl.dtsi:102 */
		twai_default: twai_default {
			phandle = < 0xe >; /* in zephyr/boards/espressif/esp32s3_devkitc/esp32s3_devkitc_procpu.dts:115 */

			/* node '/pin-controller/twai_default/group1' defined in zephyr/boards/espressif/esp32s3_devkitc/esp32s3_devkitc-pinctrl.dtsi:103 */
			group1 {
				pinmux = < 0x3a7fc5 >,
				         < 0xff9d06 >; /* in zephyr/boards/espressif/esp32s3_devkitc/esp32s3_devkitc-pinctrl.dtsi:104 */
			};
		};

		/* node '/pin-controller/ledc0_default' defined in iot_interactive_kit/boards/esp32s3_devkitc_esp32s3_procpu.overlay:98 */
		ledc0_default: ledc0_default {
			phandle = < 0xf >; /* in iot_interactive_kit/boards/esp32s3_devkitc_esp32s3_procpu.overlay:148 */

			/* node '/pin-controller/ledc0_default/group1' defined in iot_interactive_kit/boards/esp32s3_devkitc_esp32s3_procpu.overlay:99 */
			group1 {
				pinmux = < 0x24ffc6 >,
				         < 0x257fcb >,
				         < 0x267fcf >,
				         < 0x26ffd0 >; /* in iot_interactive_kit/boards/esp32s3_devkitc_esp32s3_procpu.overlay:100 */
				output-enable;         /* in iot_interactive_kit/boards/esp32s3_devkitc_esp32s3_procpu.overlay:104 */
			};
		};
	};

	/* node '/clock' defined in zephyr/dts/xtensa/espressif/esp32s3/esp32s3_common.dtsi:86 */
	clock: clock {
		compatible = "espressif,esp32-clock"; /* in zephyr/dts/xtensa/espressif/esp32s3/esp32s3_common.dtsi:87 */
		fast-clk-src = < 0x1 >;               /* in zephyr/dts/xtensa/espressif/esp32s3/esp32s3_common.dtsi:88 */
		slow-clk-src = < 0x0 >;               /* in zephyr/dts/xtensa/espressif/esp32s3/esp32s3_common.dtsi:89 */
		#clock-cells = < 0x1 >;               /* in zephyr/dts/xtensa/espressif/esp32s3/esp32s3_common.dtsi:90 */
		status = "okay";                      /* in zephyr/dts/xtensa/espressif/esp32s3/esp32s3_common.dtsi:91 */
		phandle = < 0x3 >;                    /* in zephyr/dts/xtensa/espressif/esp32s3/esp32s3_common.dtsi:192 */
	};

	/* node '/buttons' defined in zephyr/boards/espressif/esp32s3_devkitc/esp32s3_devkitc_procpu.dts:34 */
	buttons {
		compatible = "gpio-keys"; /* in zephyr/boards/espressif/esp32s3_devkitc/esp32s3_devkitc_procpu.dts:35 */

		/* node '/buttons/button_0' defined in zephyr/boards/espressif/esp32s3_devkitc/esp32s3_devkitc_procpu.dts:37 */
		button0: button_0 {
			gpios = < &gpio0 0x0 0x11 >; /* in zephyr/boards/espressif/esp32s3_devkitc/esp32s3_devkitc_procpu.dts:38 */
			label = "BOOT Button";       /* in zephyr/boards/espressif/esp32s3_devkitc/esp32s3_devkitc_procpu.dts:39 */
			zephyr,code = < 0xb >;       /* in zephyr/boards/espressif/esp32s3_devkitc/esp32s3_devkitc_procpu.dts:40 */
		};
	};

	/* node '/relay_outputs' defined in iot_interactive_kit/boards/esp32s3_devkitc_esp32s3_procpu.overlay:10 */
	relay_outputs {
		compatible = "gpio-leds"; /* in iot_interactive_kit/boards/esp32s3_devkitc_esp32s3_procpu.overlay:11 */

		/* node '/relay_outputs/relay1' defined in iot_interactive_kit/boards/esp32s3_devkitc_esp32s3_procpu.overlay:13 */
		relay1: relay1 {
			gpios = < &gpio0 0xc 0x0 >; /* in iot_interactive_kit/boards/esp32s3_devkitc_esp32s3_procpu.overlay:14 */
		};

		/* node '/relay_outputs/relay2' defined in iot_interactive_kit/boards/esp32s3_devkitc_esp32s3_procpu.overlay:17 */
		relay2: relay2 {
			gpios = < &gpio0 0xd 0x0 >; /* in iot_interactive_kit/boards/esp32s3_devkitc_esp32s3_procpu.overlay:18 */
		};
	};

	/* node '/led_outputs' defined in iot_interactive_kit/boards/esp32s3_devkitc_esp32s3_procpu.overlay:22 */
	led_outputs {
		compatible = "gpio-leds"; /* in iot_interactive_kit/boards/esp32s3_devkitc_esp32s3_procpu.overlay:23 */

		/* node '/led_outputs/led1' defined in iot_interactive_kit/boards/esp32s3_devkitc_esp32s3_procpu.overlay:25 */
		led1: led1 {
			gpios = < &gpio0 0x7 0x0 >; /* in iot_interactive_kit/boards/esp32s3_devkitc_esp32s3_procpu.overlay:26 */
		};

		/* node '/led_outputs/led2' defined in iot_interactive_kit/boards/esp32s3_devkitc_esp32s3_procpu.overlay:29 */
		led2: led2 {
			gpios = < &gpio0 0x8 0x0 >; /* in iot_interactive_kit/boards/esp32s3_devkitc_esp32s3_procpu.overlay:30 */
		};

		/* node '/led_outputs/led3' defined in iot_interactive_kit/boards/esp32s3_devkitc_esp32s3_procpu.overlay:33 */
		led3: led3 {
			gpios = < &gpio0 0x3 0x0 >; /* in iot_interactive_kit/boards/esp32s3_devkitc_esp32s3_procpu.overlay:34 */
		};
	};

	/* node '/gpio_inputs' defined in iot_interactive_kit/boards/esp32s3_devkitc_esp32s3_procpu.overlay:38 */
	gpio_inputs {
		compatible = "gpio-keys"; /* in iot_interactive_kit/boards/esp32s3_devkitc_esp32s3_procpu.overlay:39 */

		/* node '/gpio_inputs/magnetic_sw' defined in iot_interactive_kit/boards/esp32s3_devkitc_esp32s3_procpu.overlay:41 */
		magnetic_sw: magnetic_sw {
			gpios = < &gpio1 0x8 0x11 >; /* in iot_interactive_kit/boards/esp32s3_devkitc_esp32s3_procpu.overlay:42 */
		};

		/* node '/gpio_inputs/user_btn' defined in iot_interactive_kit/boards/esp32s3_devkitc_esp32s3_procpu.overlay:45 */
		user_btn: user_btn {
			gpios = < &gpio1 0x9 0x11 >; /* in iot_interactive_kit/boards/esp32s3_devkitc_esp32s3_procpu.overlay:46 */
		};
	};

	/* node '/zephyr,user' defined in iot_interactive_kit/boards/esp32s3_devkitc_esp32s3_procpu.overlay:50 */
	zephyr,user {
		io-channels = < &adc0 0x8 >,
		              < &adc0 0x9 >;      /* in iot_interactive_kit/boards/esp32s3_devkitc_esp32s3_procpu.overlay:51 */
		io-channel-names = "ldr",
		                   "water-level"; /* in iot_interactive_kit/boards/esp32s3_devkitc_esp32s3_procpu.overlay:52 */
	};

	/* node '/dht22_sensor' defined in iot_interactive_kit/boards/esp32s3_devkitc_esp32s3_procpu.overlay:55 */
	dht22_sensor: dht22_sensor {
		compatible = "aosong,dht";        /* in iot_interactive_kit/boards/esp32s3_devkitc_esp32s3_procpu.overlay:56 */
		dio-gpios = < &gpio0 0x15 0x11 >; /* in iot_interactive_kit/boards/esp32s3_devkitc_esp32s3_procpu.overlay:57 */
		dht22;                            /* in iot_interactive_kit/boards/esp32s3_devkitc_esp32s3_procpu.overlay:58 */
		status = "okay";                  /* in iot_interactive_kit/boards/esp32s3_devkitc_esp32s3_procpu.overlay:59 */
	};

	/* node '/wifi_ap' defined in iot_interactive_kit/boards/esp32s3_devkitc_esp32s3_procpu.overlay:62 */
	wifi_ap: wifi_ap {
		compatible = "espressif,esp32-wifi"; /* in iot_interactive_kit/boards/esp32s3_devkitc_esp32s3_procpu.overlay:63 */
		status = "okay";                     /* in iot_interactive_kit/boards/esp32s3_devkitc_esp32s3_procpu.overlay:64 */
	};
};
